[part 2 of 5: package /IBNvBlkSWC_4]
AUTOSAR XML (schema 00050)
package /IBNvBlkSWC_4  (continued)
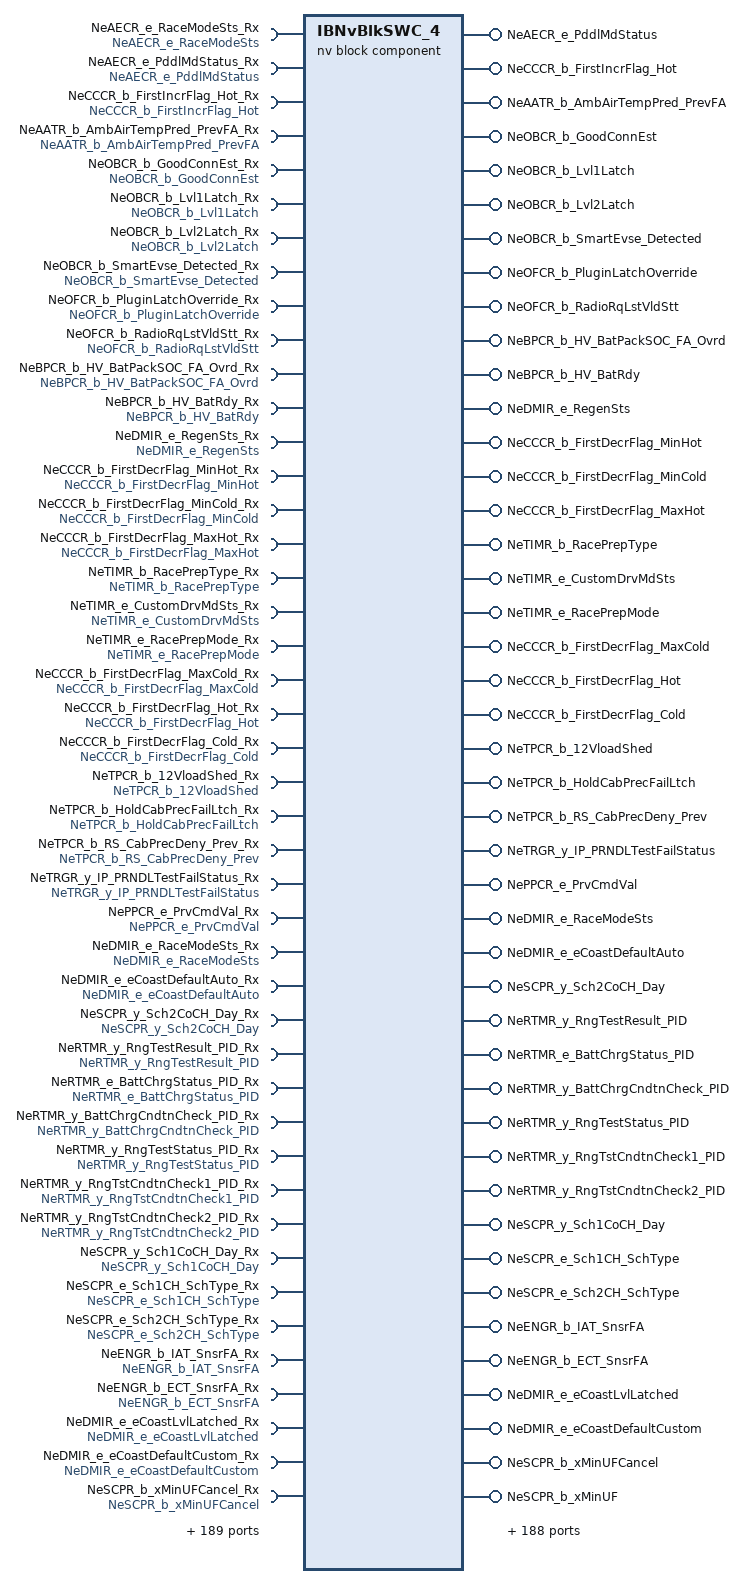
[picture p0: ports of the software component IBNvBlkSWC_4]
  nv block sw component type IBNvBlkSWC_4  (continued)
    require port NeAECR_e_RaceModeSts_Rx: nv-require-com-spec{init-value=Value:0, variable=NeAECR_e_RaceModeSts}, required-interface=NeAECR_e_RaceModeSts
    provide port NeAECR_e_PddlMdStatus: nv-provide-com-spec{ram-block-init-value=Value:0, rom-block-init-value=Value:0, variable=NeAECR_e_PddlMdStatus}, provided-interface=NeAECR_e_PddlMdStatus
    require port NeAECR_e_PddlMdStatus_Rx: nv-require-com-spec{init-value=Value:0, variable=NeAECR_e_PddlMdStatus}, required-interface=NeAECR_e_PddlMdStatus
    provide port NeCCCR_b_FirstIncrFlag_Hot: nv-provide-com-spec{ram-block-init-value=Value:0, rom-block-init-value=Value:0, variable=NeCCCR_b_FirstIncrFlag_Hot}, provided-interface=NeCCCR_b_FirstIncrFlag_Hot
    require port NeCCCR_b_FirstIncrFlag_Hot_Rx: nv-require-com-spec{init-value=Value:0, variable=NeCCCR_b_FirstIncrFlag_Hot}, required-interface=NeCCCR_b_FirstIncrFlag_Hot
    provide port NeAATR_b_AmbAirTempPred_PrevFA: nv-provide-com-spec{ram-block-init-value=Value:1, rom-block-init-value=Value:1, variable=NeAATR_b_AmbAirTempPred_PrevFA}, provided-interface=NeAATR_b_AmbAirTempPred_PrevFA
    require port NeAATR_b_AmbAirTempPred_PrevFA_Rx: nv-require-com-spec{init-value=Value:1, variable=NeAATR_b_AmbAirTempPred_PrevFA}, required-interface=NeAATR_b_AmbAirTempPred_PrevFA
    provide port NeOBCR_b_GoodConnEst: nv-provide-com-spec{ram-block-init-value=Value:1, rom-block-init-value=Value:1, variable=NeOBCR_b_GoodConnEst}, provided-interface=NeOBCR_b_GoodConnEst
    require port NeOBCR_b_GoodConnEst_Rx: nv-require-com-spec{init-value=Value:1, variable=NeOBCR_b_GoodConnEst}, required-interface=NeOBCR_b_GoodConnEst
    provide port NeOBCR_b_Lvl1Latch: nv-provide-com-spec{ram-block-init-value=Value:1, rom-block-init-value=Value:1, variable=NeOBCR_b_Lvl1Latch}, provided-interface=NeOBCR_b_Lvl1Latch
    require port NeOBCR_b_Lvl1Latch_Rx: nv-require-com-spec{init-value=Value:1, variable=NeOBCR_b_Lvl1Latch}, required-interface=NeOBCR_b_Lvl1Latch
    provide port NeOBCR_b_Lvl2Latch: nv-provide-com-spec{ram-block-init-value=Value:1, rom-block-init-value=Value:1, variable=NeOBCR_b_Lvl2Latch}, provided-interface=NeOBCR_b_Lvl2Latch
    require port NeOBCR_b_Lvl2Latch_Rx: nv-require-com-spec{init-value=Value:1, variable=NeOBCR_b_Lvl2Latch}, required-interface=NeOBCR_b_Lvl2Latch
    provide port NeOBCR_b_SmartEvse_Detected: nv-provide-com-spec{ram-block-init-value=Value:1, rom-block-init-value=Value:1, variable=NeOBCR_b_SmartEvse_Detected}, provided-interface=NeOBCR_b_SmartEvse_Detected
    require port NeOBCR_b_SmartEvse_Detected_Rx: nv-require-com-spec{init-value=Value:1, variable=NeOBCR_b_SmartEvse_Detected}, required-interface=NeOBCR_b_SmartEvse_Detected
    provide port NeOFCR_b_PluginLatchOverride: nv-provide-com-spec{ram-block-init-value=Value:0, rom-block-init-value=Value:0, variable=NeOFCR_b_PluginLatchOverride}, provided-interface=NeOFCR_b_PluginLatchOverride
    require port NeOFCR_b_PluginLatchOverride_Rx: nv-require-com-spec{init-value=Value:0, variable=NeOFCR_b_PluginLatchOverride}, required-interface=NeOFCR_b_PluginLatchOverride
    provide port NeOFCR_b_RadioRqLstVldStt: nv-provide-com-spec{ram-block-init-value=Value:0, rom-block-init-value=Value:0, variable=NeOFCR_b_RadioRqLstVldStt}, provided-interface=NeOFCR_b_RadioRqLstVldStt
    require port NeOFCR_b_RadioRqLstVldStt_Rx: nv-require-com-spec{init-value=Value:0, variable=NeOFCR_b_RadioRqLstVldStt}, required-interface=NeOFCR_b_RadioRqLstVldStt
    provide port NeBPCR_b_HV_BatPackSOC_FA_Ovrd: nv-provide-com-spec{ram-block-init-value=Value:1, rom-block-init-value=Value:1, variable=NeBPCR_b_HV_BatPackSOC_FA_Ovrd}, provided-interface=NeBPCR_b_HV_BatPackSOC_FA_Ovrd
    require port NeBPCR_b_HV_BatPackSOC_FA_Ovrd_Rx: nv-require-com-spec{init-value=Value:1, variable=NeBPCR_b_HV_BatPackSOC_FA_Ovrd}, required-interface=NeBPCR_b_HV_BatPackSOC_FA_Ovrd
    provide port NeBPCR_b_HV_BatRdy: nv-provide-com-spec{ram-block-init-value=Value:1, rom-block-init-value=Value:1, variable=NeBPCR_b_HV_BatRdy}, provided-interface=NeBPCR_b_HV_BatRdy
    require port NeBPCR_b_HV_BatRdy_Rx: nv-require-com-spec{init-value=Value:1, variable=NeBPCR_b_HV_BatRdy}, required-interface=NeBPCR_b_HV_BatRdy
    provide port NeDMIR_e_RegenSts: nv-provide-com-spec{ram-block-init-value=Value:0, rom-block-init-value=Value:0, variable=NeDMIR_e_RegenSts}, provided-interface=NeDMIR_e_RegenSts
    require port NeDMIR_e_RegenSts_Rx: nv-require-com-spec{init-value=Value:0, variable=NeDMIR_e_RegenSts}, required-interface=NeDMIR_e_RegenSts
    provide port NeCCCR_b_FirstDecrFlag_MinHot: nv-provide-com-spec{ram-block-init-value=Value:0, rom-block-init-value=Value:0, variable=NeCCCR_b_FirstDecrFlag_MinHot}, provided-interface=NeCCCR_b_FirstDecrFlag_MinHot
    require port NeCCCR_b_FirstDecrFlag_MinHot_Rx: nv-require-com-spec{init-value=Value:0, variable=NeCCCR_b_FirstDecrFlag_MinHot}, required-interface=NeCCCR_b_FirstDecrFlag_MinHot
    provide port NeCCCR_b_FirstDecrFlag_MinCold: nv-provide-com-spec{ram-block-init-value=Value:0, rom-block-init-value=Value:0, variable=NeCCCR_b_FirstDecrFlag_MinCold}, provided-interface=NeCCCR_b_FirstDecrFlag_MinCold
    require port NeCCCR_b_FirstDecrFlag_MinCold_Rx: nv-require-com-spec{init-value=Value:0, variable=NeCCCR_b_FirstDecrFlag_MinCold}, required-interface=NeCCCR_b_FirstDecrFlag_MinCold
    provide port NeCCCR_b_FirstDecrFlag_MaxHot: nv-provide-com-spec{ram-block-init-value=Value:0, rom-block-init-value=Value:0, variable=NeCCCR_b_FirstDecrFlag_MaxHot}, provided-interface=NeCCCR_b_FirstDecrFlag_MaxHot
    require port NeCCCR_b_FirstDecrFlag_MaxHot_Rx: nv-require-com-spec{init-value=Value:0, variable=NeCCCR_b_FirstDecrFlag_MaxHot}, required-interface=NeCCCR_b_FirstDecrFlag_MaxHot
    provide port NeTIMR_b_RacePrepType: nv-provide-com-spec{ram-block-init-value=Value:0, rom-block-init-value=Value:0, variable=NeTIMR_b_RacePrepType}, provided-interface=NeTIMR_b_RacePrepType
    require port NeTIMR_b_RacePrepType_Rx: nv-require-com-spec{init-value=Value:0, variable=NeTIMR_b_RacePrepType}, required-interface=NeTIMR_b_RacePrepType
    provide port NeTIMR_e_CustomDrvMdSts: nv-provide-com-spec{ram-block-init-value=Value:0, rom-block-init-value=Value:0, variable=NeTIMR_e_CustomDrvMdSts}, provided-interface=NeTIMR_e_CustomDrvMdSts
    require port NeTIMR_e_CustomDrvMdSts_Rx: nv-require-com-spec{init-value=Value:0, variable=NeTIMR_e_CustomDrvMdSts}, required-interface=NeTIMR_e_CustomDrvMdSts
    provide port NeTIMR_e_RacePrepMode: nv-provide-com-spec{ram-block-init-value=Value:0, rom-block-init-value=Value:0, variable=NeTIMR_e_RacePrepMode}, provided-interface=NeTIMR_e_RacePrepMode
    require port NeTIMR_e_RacePrepMode_Rx: nv-require-com-spec{init-value=Value:0, variable=NeTIMR_e_RacePrepMode}, required-interface=NeTIMR_e_RacePrepMode
    provide port NeCCCR_b_FirstDecrFlag_MaxCold: nv-provide-com-spec{ram-block-init-value=Value:0, rom-block-init-value=Value:0, variable=NeCCCR_b_FirstDecrFlag_MaxCold}, provided-interface=NeCCCR_b_FirstDecrFlag_MaxCold
    require port NeCCCR_b_FirstDecrFlag_MaxCold_Rx: nv-require-com-spec{init-value=Value:0, variable=NeCCCR_b_FirstDecrFlag_MaxCold}, required-interface=NeCCCR_b_FirstDecrFlag_MaxCold
    provide port NeCCCR_b_FirstDecrFlag_Hot: nv-provide-com-spec{ram-block-init-value=Value:0, rom-block-init-value=Value:0, variable=NeCCCR_b_FirstDecrFlag_Hot}, provided-interface=NeCCCR_b_FirstDecrFlag_Hot
    require port NeCCCR_b_FirstDecrFlag_Hot_Rx: nv-require-com-spec{init-value=Value:0, variable=NeCCCR_b_FirstDecrFlag_Hot}, required-interface=NeCCCR_b_FirstDecrFlag_Hot
    provide port NeCCCR_b_FirstDecrFlag_Cold: nv-provide-com-spec{ram-block-init-value=Value:0, rom-block-init-value=Value:0, variable=NeCCCR_b_FirstDecrFlag_Cold}, provided-interface=NeCCCR_b_FirstDecrFlag_Cold
    require port NeCCCR_b_FirstDecrFlag_Cold_Rx: nv-require-com-spec{init-value=Value:0, variable=NeCCCR_b_FirstDecrFlag_Cold}, required-interface=NeCCCR_b_FirstDecrFlag_Cold
    provide port NeTPCR_b_12VloadShed: nv-provide-com-spec{ram-block-init-value=Value:1, rom-block-init-value=Value:1, variable=NeTPCR_b_12VloadShed}, provided-interface=NeTPCR_b_12VloadShed
    require port NeTPCR_b_12VloadShed_Rx: nv-require-com-spec{init-value=Value:1, variable=NeTPCR_b_12VloadShed}, required-interface=NeTPCR_b_12VloadShed
    provide port NeTPCR_b_HoldCabPrecFailLtch: nv-provide-com-spec{ram-block-init-value=Value:1, rom-block-init-value=Value:1, variable=NeTPCR_b_HoldCabPrecFailLtch}, provided-interface=NeTPCR_b_HoldCabPrecFailLtch
    require port NeTPCR_b_HoldCabPrecFailLtch_Rx: nv-require-com-spec{init-value=Value:1, variable=NeTPCR_b_HoldCabPrecFailLtch}, required-interface=NeTPCR_b_HoldCabPrecFailLtch
    provide port NeTPCR_b_RS_CabPrecDeny_Prev: nv-provide-com-spec{ram-block-init-value=Value:1, rom-block-init-value=Value:1, variable=NeTPCR_b_RS_CabPrecDeny_Prev}, provided-interface=NeTPCR_b_RS_CabPrecDeny_Prev
    require port NeTPCR_b_RS_CabPrecDeny_Prev_Rx: nv-require-com-spec{init-value=Value:1, variable=NeTPCR_b_RS_CabPrecDeny_Prev}, required-interface=NeTPCR_b_RS_CabPrecDeny_Prev
    provide port NeTRGR_y_IP_PRNDLTestFailStatus: nv-provide-com-spec{ram-block-init-value=Value:0, rom-block-init-value=Value:0, variable=NeTRGR_y_IP_PRNDLTestFailStatus}, provided-interface=NeTRGR_y_IP_PRNDLTestFailStatus
    require port NeTRGR_y_IP_PRNDLTestFailStatus_Rx: nv-require-com-spec{init-value=Value:0, variable=NeTRGR_y_IP_PRNDLTestFailStatus}, required-interface=NeTRGR_y_IP_PRNDLTestFailStatus
    provide port NePPCR_e_PrvCmdVal: nv-provide-com-spec{ram-block-init-value=Value:255, rom-block-init-value=Value:255, variable=NePPCR_e_PrvCmdVal}, provided-interface=NePPCR_e_PrvCmdVal
    require port NePPCR_e_PrvCmdVal_Rx: nv-require-com-spec{init-value=Value:255, variable=NePPCR_e_PrvCmdVal}, required-interface=NePPCR_e_PrvCmdVal
    provide port NeDMIR_e_RaceModeSts: nv-provide-com-spec{ram-block-init-value=Value:0, rom-block-init-value=Value:0, variable=NeDMIR_e_RaceModeSts}, provided-interface=NeDMIR_e_RaceModeSts
    require port NeDMIR_e_RaceModeSts_Rx: nv-require-com-spec{init-value=Value:0, variable=NeDMIR_e_RaceModeSts}, required-interface=NeDMIR_e_RaceModeSts
    provide port NeDMIR_e_eCoastDefaultAuto: nv-provide-com-spec{ram-block-init-value=Value:0, rom-block-init-value=Value:0, variable=NeDMIR_e_eCoastDefaultAuto}, provided-interface=NeDMIR_e_eCoastDefaultAuto
    require port NeDMIR_e_eCoastDefaultAuto_Rx: nv-require-com-spec{init-value=Value:0, variable=NeDMIR_e_eCoastDefaultAuto}, required-interface=NeDMIR_e_eCoastDefaultAuto
    provide port NeSCPR_y_Sch2CoCH_Day: nv-provide-com-spec{ram-block-init-value=Value:0, rom-block-init-value=Value:0, variable=NeSCPR_y_Sch2CoCH_Day}, provided-interface=NeSCPR_y_Sch2CoCH_Day
    require port NeSCPR_y_Sch2CoCH_Day_Rx: nv-require-com-spec{init-value=Value:0, variable=NeSCPR_y_Sch2CoCH_Day}, required-interface=NeSCPR_y_Sch2CoCH_Day
    provide port NeRTMR_y_RngTestResult_PID: nv-provide-com-spec{ram-block-init-value=Value:0, rom-block-init-value=Value:0, variable=NeRTMR_y_RngTestResult_PID}, provided-interface=NeRTMR_y_RngTestResult_PID
    require port NeRTMR_y_RngTestResult_PID_Rx: nv-require-com-spec{init-value=Value:0, variable=NeRTMR_y_RngTestResult_PID}, required-interface=NeRTMR_y_RngTestResult_PID
    provide port NeRTMR_e_BattChrgStatus_PID: nv-provide-com-spec{ram-block-init-value=Value:0, rom-block-init-value=Value:0, variable=NeRTMR_e_BattChrgStatus_PID}, provided-interface=NeRTMR_e_BattChrgStatus_PID
    require port NeRTMR_e_BattChrgStatus_PID_Rx: nv-require-com-spec{init-value=Value:0, variable=NeRTMR_e_BattChrgStatus_PID}, required-interface=NeRTMR_e_BattChrgStatus_PID
    provide port NeRTMR_y_BattChrgCndtnCheck_PID: nv-provide-com-spec{ram-block-init-value=Value:0, rom-block-init-value=Value:0, variable=NeRTMR_y_BattChrgCndtnCheck_PID}, provided-interface=NeRTMR_y_BattChrgCndtnCheck_PID
    require port NeRTMR_y_BattChrgCndtnCheck_PID_Rx: nv-require-com-spec{init-value=Value:0, variable=NeRTMR_y_BattChrgCndtnCheck_PID}, required-interface=NeRTMR_y_BattChrgCndtnCheck_PID
    provide port NeRTMR_y_RngTestStatus_PID: nv-provide-com-spec{ram-block-init-value=Value:0, rom-block-init-value=Value:0, variable=NeRTMR_y_RngTestStatus_PID}, provided-interface=NeRTMR_y_RngTestStatus_PID
    require port NeRTMR_y_RngTestStatus_PID_Rx: nv-require-com-spec{init-value=Value:0, variable=NeRTMR_y_RngTestStatus_PID}, required-interface=NeRTMR_y_RngTestStatus_PID
    provide port NeRTMR_y_RngTstCndtnCheck1_PID: nv-provide-com-spec{ram-block-init-value=Value:0, rom-block-init-value=Value:0, variable=NeRTMR_y_RngTstCndtnCheck1_PID}, provided-interface=NeRTMR_y_RngTstCndtnCheck1_PID
    require port NeRTMR_y_RngTstCndtnCheck1_PID_Rx: nv-require-com-spec{init-value=Value:0, variable=NeRTMR_y_RngTstCndtnCheck1_PID}, required-interface=NeRTMR_y_RngTstCndtnCheck1_PID
    provide port NeRTMR_y_RngTstCndtnCheck2_PID: nv-provide-com-spec{ram-block-init-value=Value:0, rom-block-init-value=Value:0, variable=NeRTMR_y_RngTstCndtnCheck2_PID}, provided-interface=NeRTMR_y_RngTstCndtnCheck2_PID
    require port NeRTMR_y_RngTstCndtnCheck2_PID_Rx: nv-require-com-spec{init-value=Value:0, variable=NeRTMR_y_RngTstCndtnCheck2_PID}, required-interface=NeRTMR_y_RngTstCndtnCheck2_PID
    provide port NeSCPR_y_Sch1CoCH_Day: nv-provide-com-spec{ram-block-init-value=Value:0, rom-block-init-value=Value:0, variable=NeSCPR_y_Sch1CoCH_Day}, provided-interface=NeSCPR_y_Sch1CoCH_Day
    require port NeSCPR_y_Sch1CoCH_Day_Rx: nv-require-com-spec{init-value=Value:0, variable=NeSCPR_y_Sch1CoCH_Day}, required-interface=NeSCPR_y_Sch1CoCH_Day
    provide port NeSCPR_e_Sch1CH_SchType: nv-provide-com-spec{ram-block-init-value=Value:0, rom-block-init-value=Value:0, variable=NeSCPR_e_Sch1CH_SchType}, provided-interface=NeSCPR_e_Sch1CH_SchType
    require port NeSCPR_e_Sch1CH_SchType_Rx: nv-require-com-spec{init-value=Value:0, variable=NeSCPR_e_Sch1CH_SchType}, required-interface=NeSCPR_e_Sch1CH_SchType
    provide port NeSCPR_e_Sch2CH_SchType: nv-provide-com-spec{ram-block-init-value=Value:0, rom-block-init-value=Value:0, variable=NeSCPR_e_Sch2CH_SchType}, provided-interface=NeSCPR_e_Sch2CH_SchType
    require port NeSCPR_e_Sch2CH_SchType_Rx: nv-require-com-spec{init-value=Value:0, variable=NeSCPR_e_Sch2CH_SchType}, required-interface=NeSCPR_e_Sch2CH_SchType
    provide port NeENGR_b_IAT_SnsrFA: nv-provide-com-spec{ram-block-init-value=Value:0, rom-block-init-value=Value:0, variable=NeENGR_b_IAT_SnsrFA}, provided-interface=NeENGR_b_IAT_SnsrFA
    require port NeENGR_b_IAT_SnsrFA_Rx: nv-require-com-spec{init-value=Value:0, variable=NeENGR_b_IAT_SnsrFA}, required-interface=NeENGR_b_IAT_SnsrFA
    provide port NeENGR_b_ECT_SnsrFA: nv-provide-com-spec{ram-block-init-value=Value:0, rom-block-init-value=Value:0, variable=NeENGR_b_ECT_SnsrFA}, provided-interface=NeENGR_b_ECT_SnsrFA
    require port NeENGR_b_ECT_SnsrFA_Rx: nv-require-com-spec{init-value=Value:0, variable=NeENGR_b_ECT_SnsrFA}, required-interface=NeENGR_b_ECT_SnsrFA
    provide port NeDMIR_e_eCoastLvlLatched: nv-provide-com-spec{ram-block-init-value=Value:0, rom-block-init-value=Value:0, variable=NeDMIR_e_eCoastLvlLatched}, provided-interface=NeDMIR_e_eCoastLvlLatched
    require port NeDMIR_e_eCoastLvlLatched_Rx: nv-require-com-spec{init-value=Value:0, variable=NeDMIR_e_eCoastLvlLatched}, required-interface=NeDMIR_e_eCoastLvlLatched
    provide port NeDMIR_e_eCoastDefaultCustom: nv-provide-com-spec{ram-block-init-value=Value:0, rom-block-init-value=Value:0, variable=NeDMIR_e_eCoastDefaultCustom}, provided-interface=NeDMIR_e_eCoastDefaultCustom
    require port NeDMIR_e_eCoastDefaultCustom_Rx: nv-require-com-spec{init-value=Value:0, variable=NeDMIR_e_eCoastDefaultCustom}, required-interface=NeDMIR_e_eCoastDefaultCustom
    provide port NeSCPR_b_xMinUFCancel: nv-provide-com-spec{ram-block-init-value=Value:0, rom-block-init-value=Value:0, variable=NeSCPR_b_xMinUFCancel}, provided-interface=NeSCPR_b_xMinUFCancel
    require port NeSCPR_b_xMinUFCancel_Rx: nv-require-com-spec{init-value=Value:0, variable=NeSCPR_b_xMinUFCancel}, required-interface=NeSCPR_b_xMinUFCancel
    provide port NeSCPR_b_xMinUF: nv-provide-com-spec{ram-block-init-value=Value:0, rom-block-init-value=Value:0, variable=NeSCPR_b_xMinUF}, provided-interface=NeSCPR_b_xMinUF
    require port NeSCPR_b_xMinUF_Rx: nv-require-com-spec{init-value=Value:0, variable=NeSCPR_b_xMinUF}, required-interface=NeSCPR_b_xMinUF
    provide port NeSCPR_b_StopChrg: nv-provide-com-spec{ram-block-init-value=Value:0, rom-block-init-value=Value:0, variable=NeSCPR_b_StopChrg}, provided-interface=NeSCPR_b_StopChrg
    require port NeSCPR_b_StopChrg_Rx: nv-require-com-spec{init-value=Value:0, variable=NeSCPR_b_StopChrg}, required-interface=NeSCPR_b_StopChrg
    provide port NeSCPR_b_Sch2CoCH_Enbl: nv-provide-com-spec{ram-block-init-value=Value:0, rom-block-init-value=Value:0, variable=NeSCPR_b_Sch2CoCH_Enbl}, provided-interface=NeSCPR_b_Sch2CoCH_Enbl
    require port NeSCPR_b_Sch2CoCH_Enbl_Rx: nv-require-com-spec{init-value=Value:0, variable=NeSCPR_b_Sch2CoCH_Enbl}, required-interface=NeSCPR_b_Sch2CoCH_Enbl
    provide port NeHVTR_b_AntiTampFailed: nv-provide-com-spec{ram-block-init-value=Value:0, rom-block-init-value=Value:0, variable=NeHVTR_b_AntiTampFailed}, provided-interface=NeHVTR_b_AntiTampFailed
    require port NeHVTR_b_AntiTampFailed_Rx: nv-require-com-spec{init-value=Value:0, variable=NeHVTR_b_AntiTampFailed}, required-interface=NeHVTR_b_AntiTampFailed
    provide port NeSCPR_b_AllowCancel: nv-provide-com-spec{ram-block-init-value=Value:0, rom-block-init-value=Value:0, variable=NeSCPR_b_AllowCancel}, provided-interface=NeSCPR_b_AllowCancel
    require port NeSCPR_b_AllowCancel_Rx: nv-require-com-spec{init-value=Value:0, variable=NeSCPR_b_AllowCancel}, required-interface=NeSCPR_b_AllowCancel
    provide port NeSCPR_b_CancSchedIsUF: nv-provide-com-spec{ram-block-init-value=Value:0, rom-block-init-value=Value:0, variable=NeSCPR_b_CancSchedIsUF}, provided-interface=NeSCPR_b_CancSchedIsUF
    require port NeSCPR_b_CancSchedIsUF_Rx: nv-require-com-spec{init-value=Value:0, variable=NeSCPR_b_CancSchedIsUF}, required-interface=NeSCPR_b_CancSchedIsUF
    provide port NeSCPR_b_CancWindow: nv-provide-com-spec{ram-block-init-value=Value:0, rom-block-init-value=Value:0, variable=NeSCPR_b_CancWindow}, provided-interface=NeSCPR_b_CancWindow
    require port NeSCPR_b_CancWindow_Rx: nv-require-com-spec{init-value=Value:0, variable=NeSCPR_b_CancWindow}, required-interface=NeSCPR_b_CancWindow
    provide port NeSCPR_b_ChrgComplete: nv-provide-com-spec{ram-block-init-value=Value:0, rom-block-init-value=Value:0, variable=NeSCPR_b_ChrgComplete}, provided-interface=NeSCPR_b_ChrgComplete
    require port NeSCPR_b_ChrgComplete_Rx: nv-require-com-spec{init-value=Value:0, variable=NeSCPR_b_ChrgComplete}, required-interface=NeSCPR_b_ChrgComplete
    provide port NeSCPR_b_CoCH_Sch1_DNR: nv-provide-com-spec{ram-block-init-value=Value:0, rom-block-init-value=Value:0, variable=NeSCPR_b_CoCH_Sch1_DNR}, provided-interface=NeSCPR_b_CoCH_Sch1_DNR
    require port NeSCPR_b_CoCH_Sch1_DNR_Rx: nv-require-com-spec{init-value=Value:0, variable=NeSCPR_b_CoCH_Sch1_DNR}, required-interface=NeSCPR_b_CoCH_Sch1_DNR
    provide port NeSCPR_b_CoCH_Sch2_DNR: nv-provide-com-spec{ram-block-init-value=Value:0, rom-block-init-value=Value:0, variable=NeSCPR_b_CoCH_Sch2_DNR}, provided-interface=NeSCPR_b_CoCH_Sch2_DNR
    require port NeSCPR_b_CoCH_Sch2_DNR_Rx: nv-require-com-spec{init-value=Value:0, variable=NeSCPR_b_CoCH_Sch2_DNR}, required-interface=NeSCPR_b_CoCH_Sch2_DNR
    provide port NeSCPR_b_CoCh_VehLocation: nv-provide-com-spec{ram-block-init-value=Value:0, rom-block-init-value=Value:0, variable=NeSCPR_b_CoCh_VehLocation}, provided-interface=NeSCPR_b_CoCh_VehLocation
    require port NeSCPR_b_CoCh_VehLocation_Rx: nv-require-com-spec{init-value=Value:0, variable=NeSCPR_b_CoCh_VehLocation}, required-interface=NeSCPR_b_CoCh_VehLocation
    provide port NeSCPR_b_PluginLatchOverride: nv-provide-com-spec{ram-block-init-value=Value:0, rom-block-init-value=Value:0, variable=NeSCPR_b_PluginLatchOverride}, provided-interface=NeSCPR_b_PluginLatchOverride
    require port NeSCPR_b_PluginLatchOverride_Rx: nv-require-com-spec{init-value=Value:0, variable=NeSCPR_b_PluginLatchOverride}, required-interface=NeSCPR_b_PluginLatchOverride
    provide port NeSCPR_b_RadioRqLstVldStt: nv-provide-com-spec{ram-block-init-value=Value:0, rom-block-init-value=Value:0, variable=NeSCPR_b_RadioRqLstVldStt}, provided-interface=NeSCPR_b_RadioRqLstVldStt
    require port NeSCPR_b_RadioRqLstVldStt_Rx: nv-require-com-spec{init-value=Value:0, variable=NeSCPR_b_RadioRqLstVldStt}, required-interface=NeSCPR_b_RadioRqLstVldStt
    provide port NeSCPR_b_Sch1CoCH_Enbl: nv-provide-com-spec{ram-block-init-value=Value:0, rom-block-init-value=Value:0, variable=NeSCPR_b_Sch1CoCH_Enbl}, provided-interface=NeSCPR_b_Sch1CoCH_Enbl
    require port NeSCPR_b_Sch1CoCH_Enbl_Rx: nv-require-com-spec{init-value=Value:0, variable=NeSCPR_b_Sch1CoCH_Enbl}, required-interface=NeSCPR_b_Sch1CoCH_Enbl
    provide port EePLTR_t_RTCTime: nv-provide-com-spec{ram-block-init-value=Value:0, rom-block-init-value=Value:0, variable=EePLTR_t_RTCTime}, provided-interface=EePLTR_t_RTCTime
    require port EePLTR_t_RTCTime_Rx: nv-require-com-spec{init-value=Value:0, variable=EePLTR_t_RTCTime}, required-interface=EePLTR_t_RTCTime
    provide port EeHCDR_t_RealTime_Comp_On: nv-provide-com-spec{ram-block-init-value=Value:0, rom-block-init-value=Value:0, variable=EeHCDR_t_RealTime_Comp_On}, provided-interface=EeHCDR_t_RealTime_Comp_On
    require port EeHCDR_t_RealTime_Comp_On_Rx: nv-require-com-spec{init-value=Value:0, variable=EeHCDR_t_RealTime_Comp_On}, required-interface=EeHCDR_t_RealTime_Comp_On
    provide port EeHCDR_t_RealTime_Comp_Off: nv-provide-com-spec{ram-block-init-value=Value:0, rom-block-init-value=Value:0, variable=EeHCDR_t_RealTime_Comp_Off}, provided-interface=EeHCDR_t_RealTime_Comp_Off
    require port EeHCDR_t_RealTime_Comp_Off_Rx: nv-require-com-spec{init-value=Value:0, variable=EeHCDR_t_RealTime_Comp_Off}, required-interface=EeHCDR_t_RealTime_Comp_Off
    provide port EeERER_l_EEPROM_EstRange: nv-provide-com-spec{ram-block-init-value=Value:0, rom-block-init-value=Value:0, variable=EeERER_l_EEPROM_EstRange}, provided-interface=EeERER_l_EEPROM_EstRange
    require port EeERER_l_EEPROM_EstRange_Rx: nv-require-com-spec{init-value=Value:0, variable=EeERER_l_EEPROM_EstRange}, required-interface=EeERER_l_EEPROM_EstRange
    provide port EeDCCR_t_V2GPerfInhibTime: nv-provide-com-spec{ram-block-init-value=Value:0, rom-block-init-value=Value:0, variable=EeDCCR_t_V2GPerfInhibTime}, provided-interface=EeDCCR_t_V2GPerfInhibTime
    require port EeDCCR_t_V2GPerfInhibTime_Rx: nv-require-com-spec{init-value=Value:0, variable=EeDCCR_t_V2GPerfInhibTime}, required-interface=EeDCCR_t_V2GPerfInhibTime
    provide port EeDCCR_t_V2GTime: nv-provide-com-spec{ram-block-init-value=Value:0, rom-block-init-value=Value:0, variable=EeDCCR_t_V2GTime}, provided-interface=EeDCCR_t_V2GTime
    require port EeDCCR_t_V2GTime_Rx: nv-require-com-spec{init-value=Value:0, variable=EeDCCR_t_V2GTime}, required-interface=EeDCCR_t_V2GTime
    provide port EeERER_F_EEPROM_WhperKM: nv-provide-com-spec{ram-block-init-value=Value:0, rom-block-init-value=Value:0, variable=EeERER_F_EEPROM_WhperKM}, provided-interface=EeERER_F_EEPROM_WhperKM
    require port EeERER_F_EEPROM_WhperKM_Rx: nv-require-com-spec{init-value=Value:0, variable=EeERER_F_EEPROM_WhperKM}, required-interface=EeERER_F_EEPROM_WhperKM
    provide port EeERER_k_Modify_Factor: nv-provide-com-spec{ram-block-init-value=Value:0, rom-block-init-value=Value:0, variable=EeERER_k_Modify_Factor}, provided-interface=EeERER_k_Modify_Factor
    require port EeERER_k_Modify_Factor_Rx: nv-require-com-spec{init-value=Value:0, variable=EeERER_k_Modify_Factor}, required-interface=EeERER_k_Modify_Factor
    provide port EeERER_l_VehDist_Delta: nv-provide-com-spec{ram-block-init-value=Value:0, rom-block-init-value=Value:0, variable=EeERER_l_VehDist_Delta}, provided-interface=EeERER_l_VehDist_Delta
    require port EeERER_l_VehDist_Delta_Rx: nv-require-com-spec{init-value=Value:0, variable=EeERER_l_VehDist_Delta}, required-interface=EeERER_l_VehDist_Delta
    provide port EePWDR_t_DAP_FA_InitTime: nv-provide-com-spec{ram-block-init-value=Value:0, rom-block-init-value=Value:0, variable=EePWDR_t_DAP_FA_InitTime}, provided-interface=EePWDR_t_DAP_FA_InitTime
    require port EePWDR_t_DAP_FA_InitTime_Rx: nv-require-com-spec{init-value=Value:0, variable=EePWDR_t_DAP_FA_InitTime}, required-interface=EePWDR_t_DAP_FA_InitTime
    provide port EePWDR_t_DAP_FA_ElapsedTime: nv-provide-com-spec{ram-block-init-value=Value:0, rom-block-init-value=Value:0, variable=EePWDR_t_DAP_FA_ElapsedTime}, provided-interface=EePWDR_t_DAP_FA_ElapsedTime
    require port EePWDR_t_DAP_FA_ElapsedTime_Rx: nv-require-com-spec{init-value=Value:0, variable=EePWDR_t_DAP_FA_ElapsedTime}, required-interface=EePWDR_t_DAP_FA_ElapsedTime
    provide port EePWDR_l_DAP_FA_DistTravld: nv-provide-com-spec{ram-block-init-value=Value:0, rom-block-init-value=Value:0, variable=EePWDR_l_DAP_FA_DistTravld}, provided-interface=EePWDR_l_DAP_FA_DistTravld
    require port EePWDR_l_DAP_FA_DistTravld_Rx: nv-require-com-spec{init-value=Value:0, variable=EePWDR_l_DAP_FA_DistTravld}, required-interface=EePWDR_l_DAP_FA_DistTravld
    provide port EeOBCR_t_EstTimeofChrg_Lv1: nv-provide-com-spec{ram-block-init-value=Value:4294967295, rom-block-init-value=Value:4294967295, variable=EeOBCR_t_EstTimeofChrg_Lv1}, provided-interface=EeOBCR_t_EstTimeofChrg_Lv1
    require port EeOBCR_t_EstTimeofChrg_Lv1_Rx: nv-require-com-spec{init-value=Value:4294967295, variable=EeOBCR_t_EstTimeofChrg_Lv1}, required-interface=EeOBCR_t_EstTimeofChrg_Lv1
    provide port EeOBCR_t_EstTimeofChrg_Lv2: nv-provide-com-spec{ram-block-init-value=Value:4294967295, rom-block-init-value=Value:4294967295, variable=EeOBCR_t_EstTimeofChrg_Lv2}, provided-interface=EeOBCR_t_EstTimeofChrg_Lv2
    require port EeOBCR_t_EstTimeofChrg_Lv2_Rx: nv-require-com-spec{init-value=Value:4294967295, variable=EeOBCR_t_EstTimeofChrg_Lv2}, required-interface=EeOBCR_t_EstTimeofChrg_Lv2
    provide port EeIMOR_M_Rand1_prev: nv-provide-com-spec{ram-block-init-value=Value:4294967295, rom-block-init-value=Value:4294967295, variable=EeIMOR_M_Rand1_prev}, provided-interface=EeIMOR_M_Rand1_prev
    require port EeIMOR_M_Rand1_prev_Rx: nv-require-com-spec{init-value=Value:4294967295, variable=EeIMOR_M_Rand1_prev}, required-interface=EeIMOR_M_Rand1_prev
    provide port EeIMOR_M_Rand2_prev: nv-provide-com-spec{ram-block-init-value=Value:4294967295, rom-block-init-value=Value:4294967295, variable=EeIMOR_M_Rand2_prev}, provided-interface=EeIMOR_M_Rand2_prev
    require port EeIMOR_M_Rand2_prev_Rx: nv-require-com-spec{init-value=Value:4294967295, variable=EeIMOR_M_Rand2_prev}, required-interface=EeIMOR_M_Rand2_prev
    provide port EeIMOR_M_Rand3_prev: nv-provide-com-spec{ram-block-init-value=Value:4294967295, rom-block-init-value=Value:4294967295, variable=EeIMOR_M_Rand3_prev}, provided-interface=EeIMOR_M_Rand3_prev
    require port EeIMOR_M_Rand3_prev_Rx: nv-require-com-spec{init-value=Value:4294967295, variable=EeIMOR_M_Rand3_prev}, required-interface=EeIMOR_M_Rand3_prev
    provide port EeIMOR_M_Rand4_prev: nv-provide-com-spec{ram-block-init-value=Value:4294967295, rom-block-init-value=Value:4294967295, variable=EeIMOR_M_Rand4_prev}, provided-interface=EeIMOR_M_Rand4_prev
    require port EeIMOR_M_Rand4_prev_Rx: nv-require-com-spec{init-value=Value:4294967295, variable=EeIMOR_M_Rand4_prev}, required-interface=EeIMOR_M_Rand4_prev
    provide port EePLTR_t_PowerdownTime: nv-provide-com-spec{ram-block-init-value=Value:0, rom-block-init-value=Value:0, variable=EePLTR_t_PowerdownTime}, provided-interface=EePLTR_t_PowerdownTime
    require port EePLTR_t_PowerdownTime_Rx: nv-require-com-spec{init-value=Value:0, variable=EePLTR_t_PowerdownTime}, required-interface=EePLTR_t_PowerdownTime
    provide port EeTPCR_e_HoldClusterMsg: nv-provide-com-spec{ram-block-init-value=Value:32767, rom-block-init-value=Value:32767, variable=EeTPCR_e_HoldClusterMsg}, provided-interface=EeTPCR_e_HoldClusterMsg
    require port EeTPCR_e_HoldClusterMsg_Rx: nv-require-com-spec{init-value=Value:32767, variable=EeTPCR_e_HoldClusterMsg}, required-interface=EeTPCR_e_HoldClusterMsg
    provide port EeTPCR_e_HoldClusterMsg_KHC: nv-provide-com-spec{ram-block-init-value=Value:32767, rom-block-init-value=Value:32767, variable=EeTPCR_e_HoldClusterMsg_KHC}, provided-interface=EeTPCR_e_HoldClusterMsg_KHC
    require port EeTPCR_e_HoldClusterMsg_KHC_Rx: nv-require-com-spec{init-value=Value:32767, variable=EeTPCR_e_HoldClusterMsg_KHC}, required-interface=EeTPCR_e_HoldClusterMsg_KHC
    provide port EePLTR_e_ShippingMode: nv-provide-com-spec{ram-block-init-value=Value:0, rom-block-init-value=Value:0, variable=EePLTR_e_ShippingMode}, provided-interface=EePLTR_e_ShippingMode
    require port EePLTR_e_ShippingMode_Rx: nv-require-com-spec{init-value=Value:0, variable=EePLTR_e_ShippingMode}, required-interface=EePLTR_e_ShippingMode
    provide port EeDMIR_d_ChargeTypeCnf: nv-provide-com-spec{ram-block-init-value=Value:0, rom-block-init-value=Value:0, variable=EeDMIR_d_ChargeTypeCnf}, provided-interface=EeDMIR_d_ChargeTypeCnf
    require port EeDMIR_d_ChargeTypeCnf_Rx: nv-require-com-spec{init-value=Value:0, variable=EeDMIR_d_ChargeTypeCnf}, required-interface=EeDMIR_d_ChargeTypeCnf
    provide port EeDMIR_d_TgtSOCRngCnf: nv-provide-com-spec{ram-block-init-value=Value:0, rom-block-init-value=Value:0, variable=EeDMIR_d_TgtSOCRngCnf}, provided-interface=EeDMIR_d_TgtSOCRngCnf
    require port EeDMIR_d_TgtSOCRngCnf_Rx: nv-require-com-spec{init-value=Value:0, variable=EeDMIR_d_TgtSOCRngCnf}, required-interface=EeDMIR_d_TgtSOCRngCnf
    provide port EeIMOR_e_BuildAssemblyModeStat: nv-provide-com-spec{ram-block-init-value=Value:32767, rom-block-init-value=Value:32767, variable=EeIMOR_e_BuildAssemblyModeStat}, provided-interface=EeIMOR_e_BuildAssemblyModeStat
    require port EeIMOR_e_BuildAssemblyModeStat_Rx: nv-require-com-spec{init-value=Value:32767, variable=EeIMOR_e_BuildAssemblyModeStat}, required-interface=EeIMOR_e_BuildAssemblyModeStat
    provide port EeHVTR_e_StrtCmd_SrvcProc1320: nv-provide-com-spec{ram-block-init-value=Value:2, rom-block-init-value=Value:2, variable=EeHVTR_e_StrtCmd_SrvcProc1320}, provided-interface=EeHVTR_e_StrtCmd_SrvcProc1320
    require port EeHVTR_e_StrtCmd_SrvcProc1320_Rx: nv-require-com-spec{init-value=Value:2, variable=EeHVTR_e_StrtCmd_SrvcProc1320}, required-interface=EeHVTR_e_StrtCmd_SrvcProc1320
    provide port EePLTR_e_RTCStatus: nv-provide-com-spec{ram-block-init-value=Value:0, rom-block-init-value=Value:0, variable=EePLTR_e_RTCStatus}, provided-interface=EePLTR_e_RTCStatus
    require port EePLTR_e_RTCStatus_Rx: nv-require-com-spec{init-value=Value:0, variable=EePLTR_e_RTCStatus}, required-interface=EePLTR_e_RTCStatus
    provide port EeERER_e_DriveMode: nv-provide-com-spec{ram-block-init-value=Value:0, rom-block-init-value=Value:0, variable=EeERER_e_DriveMode}, provided-interface=EeERER_e_DriveMode
    require port EeERER_e_DriveMode_Rx: nv-require-com-spec{init-value=Value:0, variable=EeERER_e_DriveMode}, required-interface=EeERER_e_DriveMode
    provide port EeERER_e_TurtleMode: nv-provide-com-spec{ram-block-init-value=Value:0, rom-block-init-value=Value:0, variable=EeERER_e_TurtleMode}, provided-interface=EeERER_e_TurtleMode
    require port EeERER_e_TurtleMode_Rx: nv-require-com-spec{init-value=Value:0, variable=EeERER_e_TurtleMode}, required-interface=EeERER_e_TurtleMode
    provide port EeAECR_e_MaxRegenDsrdSt: nv-provide-com-spec{ram-block-init-value=Value:0, rom-block-init-value=Value:0, variable=EeAECR_e_MaxRegenDsrdSt}, provided-interface=EeAECR_e_MaxRegenDsrdSt
    require port EeAECR_e_MaxRegenDsrdSt_Rx: nv-require-com-spec{init-value=Value:0, variable=EeAECR_e_MaxRegenDsrdSt}, required-interface=EeAECR_e_MaxRegenDsrdSt
    provide port EeOBCR_e_ChargingSystemSts: nv-provide-com-spec{ram-block-init-value=Value:32767, rom-block-init-value=Value:32767, variable=EeOBCR_e_ChargingSystemSts}, provided-interface=EeOBCR_e_ChargingSystemSts
    require port EeOBCR_e_ChargingSystemSts_Rx: nv-require-com-spec{init-value=Value:32767, variable=EeOBCR_e_ChargingSystemSts}, required-interface=EeOBCR_e_ChargingSystemSts
    provide port EeOBCR_e_ChargingLevel: nv-provide-com-spec{ram-block-init-value=Value:32767, rom-block-init-value=Value:32767, variable=EeOBCR_e_ChargingLevel}, provided-interface=EeOBCR_e_ChargingLevel
    require port EeOBCR_e_ChargingLevel_Rx: nv-require-com-spec{init-value=Value:32767, variable=EeOBCR_e_ChargingLevel}, required-interface=EeOBCR_e_ChargingLevel
    provide port EeCHFR_b_ChrgSysFault: nv-provide-com-spec{ram-block-init-value=Value:0, rom-block-init-value=Value:0, variable=EeCHFR_b_ChrgSysFault}, provided-interface=EeCHFR_b_ChrgSysFault
    require port EeCHFR_b_ChrgSysFault_Rx: nv-require-com-spec{init-value=Value:0, variable=EeCHFR_b_ChrgSysFault}, required-interface=EeCHFR_b_ChrgSysFault
    provide port EeIMOR_y_MMKey1org22_Mem: nv-provide-com-spec{ram-block-init-value=Value:255, rom-block-init-value=Value:255, variable=EeIMOR_y_MMKey1org22_Mem}, provided-interface=EeIMOR_y_MMKey1org22_Mem
    require port EeIMOR_y_MMKey1org22_Mem_Rx: nv-require-com-spec{init-value=Value:255, variable=EeIMOR_y_MMKey1org22_Mem}, required-interface=EeIMOR_y_MMKey1org22_Mem
    provide port EeOBCR_b_PluggedIn: nv-provide-com-spec{ram-block-init-value=Value:0, rom-block-init-value=Value:0, variable=EeOBCR_b_PluggedIn}, provided-interface=EeOBCR_b_PluggedIn
    require port EeOBCR_b_PluggedIn_Rx: nv-require-com-spec{init-value=Value:0, variable=EeOBCR_b_PluggedIn}, required-interface=EeOBCR_b_PluggedIn
    provide port EePLTR_b_RTC_CurrentTimeFA: nv-provide-com-spec{ram-block-init-value=Value:0, rom-block-init-value=Value:0, variable=EePLTR_b_RTC_CurrentTimeFA}, provided-interface=EePLTR_b_RTC_CurrentTimeFA
    require port EePLTR_b_RTC_CurrentTimeFA_Rx: nv-require-com-spec{init-value=Value:0, variable=EePLTR_b_RTC_CurrentTimeFA}, required-interface=EePLTR_b_RTC_CurrentTimeFA
    provide port EeIMOR_b_AuthCmd08_InFlag: nv-provide-com-spec{ram-block-init-value=Value:0, rom-block-init-value=Value:0, variable=EeIMOR_b_AuthCmd08_InFlag}, provided-interface=EeIMOR_b_AuthCmd08_InFlag
    require port EeIMOR_b_AuthCmd08_InFlag_Rx: nv-require-com-spec{init-value=Value:0, variable=EeIMOR_b_AuthCmd08_InFlag}, required-interface=EeIMOR_b_AuthCmd08_InFlag
    provide port EeIMOR_b_AuthCmd07_InFlag: nv-provide-com-spec{ram-block-init-value=Value:0, rom-block-init-value=Value:0, variable=EeIMOR_b_AuthCmd07_InFlag}, provided-interface=EeIMOR_b_AuthCmd07_InFlag
    require port EeIMOR_b_AuthCmd07_InFlag_Rx: nv-require-com-spec{init-value=Value:0, variable=EeIMOR_b_AuthCmd07_InFlag}, required-interface=EeIMOR_b_AuthCmd07_InFlag
    provide port EeIMOR_b_AuthCmd06_InFlag: nv-provide-com-spec{ram-block-init-value=Value:0, rom-block-init-value=Value:0, variable=EeIMOR_b_AuthCmd06_InFlag}, provided-interface=EeIMOR_b_AuthCmd06_InFlag
    require port EeIMOR_b_AuthCmd06_InFlag_Rx: nv-require-com-spec{init-value=Value:0, variable=EeIMOR_b_AuthCmd06_InFlag}, required-interface=EeIMOR_b_AuthCmd06_InFlag
    provide port EeIMOR_b_AuthCmd05_InFlag: nv-provide-com-spec{ram-block-init-value=Value:0, rom-block-init-value=Value:0, variable=EeIMOR_b_AuthCmd05_InFlag}, provided-interface=EeIMOR_b_AuthCmd05_InFlag
    require port EeIMOR_b_AuthCmd05_InFlag_Rx: nv-require-com-spec{init-value=Value:0, variable=EeIMOR_b_AuthCmd05_InFlag}, required-interface=EeIMOR_b_AuthCmd05_InFlag
    provide port EeIMOR_b_AuthCmd04_InFlag: nv-provide-com-spec{ram-block-init-value=Value:0, rom-block-init-value=Value:0, variable=EeIMOR_b_AuthCmd04_InFlag}, provided-interface=EeIMOR_b_AuthCmd04_InFlag
    require port EeIMOR_b_AuthCmd04_InFlag_Rx: nv-require-com-spec{init-value=Value:0, variable=EeIMOR_b_AuthCmd04_InFlag}, required-interface=EeIMOR_b_AuthCmd04_InFlag
    provide port EeIMOR_b_AuthCmd03_InFlag: nv-provide-com-spec{ram-block-init-value=Value:0, rom-block-init-value=Value:0, variable=EeIMOR_b_AuthCmd03_InFlag}, provided-interface=EeIMOR_b_AuthCmd03_InFlag
    require port EeIMOR_b_AuthCmd03_InFlag_Rx: nv-require-com-spec{init-value=Value:0, variable=EeIMOR_b_AuthCmd03_InFlag}, required-interface=EeIMOR_b_AuthCmd03_InFlag
    provide port EeIMOR_b_AuthCmd02_InFlag: nv-provide-com-spec{ram-block-init-value=Value:0, rom-block-init-value=Value:0, variable=EeIMOR_b_AuthCmd02_InFlag}, provided-interface=EeIMOR_b_AuthCmd02_InFlag
    require port EeIMOR_b_AuthCmd02_InFlag_Rx: nv-require-com-spec{init-value=Value:0, variable=EeIMOR_b_AuthCmd02_InFlag}, required-interface=EeIMOR_b_AuthCmd02_InFlag
    provide port EeIMOR_b_AuthCmd09_InFlag: nv-provide-com-spec{ram-block-init-value=Value:0, rom-block-init-value=Value:0, variable=EeIMOR_b_AuthCmd09_InFlag}, provided-interface=EeIMOR_b_AuthCmd09_InFlag
    require port EeIMOR_b_AuthCmd09_InFlag_Rx: nv-require-com-spec{init-value=Value:0, variable=EeIMOR_b_AuthCmd09_InFlag}, required-interface=EeIMOR_b_AuthCmd09_InFlag
    provide port EeIMOR_y_MMKey_3_Mem: nv-provide-com-spec{ram-block-init-value=Value:255, rom-block-init-value=Value:255, variable=EeIMOR_y_MMKey_3_Mem}, provided-interface=EeIMOR_y_MMKey_3_Mem
    require port EeIMOR_y_MMKey_3_Mem_Rx: nv-require-com-spec{init-value=Value:255, variable=EeIMOR_y_MMKey_3_Mem}, required-interface=EeIMOR_y_MMKey_3_Mem
    provide port EeIMOR_b_VC_VehCfg6_Stat_rec: nv-provide-com-spec{ram-block-init-value=Value:0, rom-block-init-value=Value:0, variable=EeIMOR_b_VC_VehCfg6_Stat_rec}, provided-interface=EeIMOR_b_VC_VehCfg6_Stat_rec
    require port EeIMOR_b_VC_VehCfg6_Stat_rec_Rx: nv-require-com-spec{init-value=Value:0, variable=EeIMOR_b_VC_VehCfg6_Stat_rec}, required-interface=EeIMOR_b_VC_VehCfg6_Stat_rec
    provide port EeIMOR_b_VC_VehCfg4_Stat_rec: nv-provide-com-spec{ram-block-init-value=Value:0, rom-block-init-value=Value:0, variable=EeIMOR_b_VC_VehCfg4_Stat_rec}, provided-interface=EeIMOR_b_VC_VehCfg4_Stat_rec
    require port EeIMOR_b_VC_VehCfg4_Stat_rec_Rx: nv-require-com-spec{init-value=Value:0, variable=EeIMOR_b_VC_VehCfg4_Stat_rec}, required-interface=EeIMOR_b_VC_VehCfg4_Stat_rec
    provide port EeIMOR_b_VC_VehCfg3_Stat_rec: nv-provide-com-spec{ram-block-init-value=Value:0, rom-block-init-value=Value:0, variable=EeIMOR_b_VC_VehCfg3_Stat_rec}, provided-interface=EeIMOR_b_VC_VehCfg3_Stat_rec
    require port EeIMOR_b_VC_VehCfg3_Stat_rec_Rx: nv-require-com-spec{init-value=Value:0, variable=EeIMOR_b_VC_VehCfg3_Stat_rec}, required-interface=EeIMOR_b_VC_VehCfg3_Stat_rec
    provide port EeIMOR_b_VC_VehCfg2_Stat_rec: nv-provide-com-spec{ram-block-init-value=Value:0, rom-block-init-value=Value:0, variable=EeIMOR_b_VC_VehCfg2_Stat_rec}, provided-interface=EeIMOR_b_VC_VehCfg2_Stat_rec
    require port EeIMOR_b_VC_VehCfg2_Stat_rec_Rx: nv-require-com-spec{init-value=Value:0, variable=EeIMOR_b_VC_VehCfg2_Stat_rec}, required-interface=EeIMOR_b_VC_VehCfg2_Stat_rec
    provide port EeIMOR_b_ORC_Health_rec: nv-provide-com-spec{ram-block-init-value=Value:0, rom-block-init-value=Value:0, variable=EeIMOR_b_ORC_Health_rec}, provided-interface=EeIMOR_b_ORC_Health_rec
    require port EeIMOR_b_ORC_Health_rec_Rx: nv-require-com-spec{init-value=Value:0, variable=EeIMOR_b_ORC_Health_rec}, required-interface=EeIMOR_b_ORC_Health_rec
    provide port EeIMOR_b_MMKey_6Flag: nv-provide-com-spec{ram-block-init-value=Value:0, rom-block-init-value=Value:0, variable=EeIMOR_b_MMKey_6Flag}, provided-interface=EeIMOR_b_MMKey_6Flag
    require port EeIMOR_b_MMKey_6Flag_Rx: nv-require-com-spec{init-value=Value:0, variable=EeIMOR_b_MMKey_6Flag}, required-interface=EeIMOR_b_MMKey_6Flag
    provide port EeIMOR_b_MMKey_5Flag: nv-provide-com-spec{ram-block-init-value=Value:0, rom-block-init-value=Value:0, variable=EeIMOR_b_MMKey_5Flag}, provided-interface=EeIMOR_b_MMKey_5Flag
    require port EeIMOR_b_MMKey_5Flag_Rx: nv-require-com-spec{init-value=Value:0, variable=EeIMOR_b_MMKey_5Flag}, required-interface=EeIMOR_b_MMKey_5Flag
    provide port EeIMOR_b_MMKey_4Flag: nv-provide-com-spec{ram-block-init-value=Value:0, rom-block-init-value=Value:0, variable=EeIMOR_b_MMKey_4Flag}, provided-interface=EeIMOR_b_MMKey_4Flag
    require port EeIMOR_b_MMKey_4Flag_Rx: nv-require-com-spec{init-value=Value:0, variable=EeIMOR_b_MMKey_4Flag}, required-interface=EeIMOR_b_MMKey_4Flag
    provide port EeIMOR_b_MMKey_3Flag: nv-provide-com-spec{ram-block-init-value=Value:0, rom-block-init-value=Value:0, variable=EeIMOR_b_MMKey_3Flag}, provided-interface=EeIMOR_b_MMKey_3Flag
    require port EeIMOR_b_MMKey_3Flag_Rx: nv-require-com-spec{init-value=Value:0, variable=EeIMOR_b_MMKey_3Flag}, required-interface=EeIMOR_b_MMKey_3Flag
    provide port EeIMOR_b_MMKey1org22Flag: nv-provide-com-spec{ram-block-init-value=Value:0, rom-block-init-value=Value:0, variable=EeIMOR_b_MMKey1org22Flag}, provided-interface=EeIMOR_b_MMKey1org22Flag
    require port EeIMOR_b_MMKey1org22Flag_Rx: nv-require-com-spec{init-value=Value:0, variable=EeIMOR_b_MMKey1org22Flag}, required-interface=EeIMOR_b_MMKey1org22Flag
    provide port EeIMOR_b_MMKey1org21Flag: nv-provide-com-spec{ram-block-init-value=Value:0, rom-block-init-value=Value:0, variable=EeIMOR_b_MMKey1org21Flag}, provided-interface=EeIMOR_b_MMKey1org21Flag
    require port EeIMOR_b_MMKey1org21Flag_Rx: nv-require-com-spec{init-value=Value:0, variable=EeIMOR_b_MMKey1org21Flag}, required-interface=EeIMOR_b_MMKey1org21Flag
    provide port EeIMOR_b_MKeyStrToE2: nv-provide-com-spec{ram-block-init-value=Value:0, rom-block-init-value=Value:0, variable=EeIMOR_b_MKeyStrToE2}, provided-interface=EeIMOR_b_MKeyStrToE2
    require port EeIMOR_b_MKeyStrToE2_Rx: nv-require-com-spec{init-value=Value:0, variable=EeIMOR_b_MKeyStrToE2}, required-interface=EeIMOR_b_MKeyStrToE2
    provide port EeIMOR_b_ImmoAuthValid_Mem: nv-provide-com-spec{ram-block-init-value=Value:0, rom-block-init-value=Value:0, variable=EeIMOR_b_ImmoAuthValid_Mem}, provided-interface=EeIMOR_b_ImmoAuthValid_Mem
    require port EeIMOR_b_ImmoAuthValid_Mem_Rx: nv-require-com-spec{init-value=Value:0, variable=EeIMOR_b_ImmoAuthValid_Mem}, required-interface=EeIMOR_b_ImmoAuthValid_Mem
    provide port EeIMOR_b_ImmoAuthValid_ECMMem: nv-provide-com-spec{ram-block-init-value=Value:0, rom-block-init-value=Value:0, variable=EeIMOR_b_ImmoAuthValid_ECMMem}, provided-interface=EeIMOR_b_ImmoAuthValid_ECMMem
    require port EeIMOR_b_ImmoAuthValid_ECMMem_Rx: nv-require-com-spec{init-value=Value:0, variable=EeIMOR_b_ImmoAuthValid_ECMMem}, required-interface=EeIMOR_b_ImmoAuthValid_ECMMem
    provide port EeIMOR_b_CodeRecCmplt_Mem: nv-provide-com-spec{ram-block-init-value=Value:0, rom-block-init-value=Value:0, variable=EeIMOR_b_CodeRecCmplt_Mem}, provided-interface=EeIMOR_b_CodeRecCmplt_Mem
    require port EeIMOR_b_CodeRecCmplt_Mem_Rx: nv-require-com-spec{init-value=Value:0, variable=EeIMOR_b_CodeRecCmplt_Mem}, required-interface=EeIMOR_b_CodeRecCmplt_Mem
    provide port EeIMOR_b_CntrlEncdResFlag: nv-provide-com-spec{ram-block-init-value=Value:0, rom-block-init-value=Value:0, variable=EeIMOR_b_CntrlEncdResFlag}, provided-interface=EeIMOR_b_CntrlEncdResFlag
    require port EeIMOR_b_CntrlEncdResFlag_Rx: nv-require-com-spec{init-value=Value:0, variable=EeIMOR_b_CntrlEncdResFlag}, required-interface=EeIMOR_b_CntrlEncdResFlag
    provide port EeIMOR_b_AuthCmdCntrlEncdRespFlag: nv-provide-com-spec{ram-block-init-value=Value:0, rom-block-init-value=Value:0, variable=EeIMOR_b_AuthCmdCntrlEncdRespFlag}, provided-interface=EeIMOR_b_AuthCmdCntrlEncdRespFlag
    require port EeIMOR_b_AuthCmdCntrlEncdRespFlag_Rx: nv-require-com-spec{init-value=Value:0, variable=EeIMOR_b_AuthCmdCntrlEncdRespFlag}, required-interface=EeIMOR_b_AuthCmdCntrlEncdRespFlag
    provide port EeIMOR_b_AuthCmd15_InFlag: nv-provide-com-spec{ram-block-init-value=Value:0, rom-block-init-value=Value:0, variable=EeIMOR_b_AuthCmd15_InFlag}, provided-interface=EeIMOR_b_AuthCmd15_InFlag
    require port EeIMOR_b_AuthCmd15_InFlag_Rx: nv-require-com-spec{init-value=Value:0, variable=EeIMOR_b_AuthCmd15_InFlag}, required-interface=EeIMOR_b_AuthCmd15_InFlag
    provide port EeIMOR_b_AuthCmd14_InFlag: nv-provide-com-spec{ram-block-init-value=Value:0, rom-block-init-value=Value:0, variable=EeIMOR_b_AuthCmd14_InFlag}, provided-interface=EeIMOR_b_AuthCmd14_InFlag
    require port EeIMOR_b_AuthCmd14_InFlag_Rx: nv-require-com-spec{init-value=Value:0, variable=EeIMOR_b_AuthCmd14_InFlag}, required-interface=EeIMOR_b_AuthCmd14_InFlag
    provide port EeIMOR_b_AuthCmd13_InFlag: nv-provide-com-spec{ram-block-init-value=Value:0, rom-block-init-value=Value:0, variable=EeIMOR_b_AuthCmd13_InFlag}, provided-interface=EeIMOR_b_AuthCmd13_InFlag
    require port EeIMOR_b_AuthCmd13_InFlag_Rx: nv-require-com-spec{init-value=Value:0, variable=EeIMOR_b_AuthCmd13_InFlag}, required-interface=EeIMOR_b_AuthCmd13_InFlag
    provide port EeIMOR_b_AuthCmd12_InFlag: nv-provide-com-spec{ram-block-init-value=Value:0, rom-block-init-value=Value:0, variable=EeIMOR_b_AuthCmd12_InFlag}, provided-interface=EeIMOR_b_AuthCmd12_InFlag
    require port EeIMOR_b_AuthCmd12_InFlag_Rx: nv-require-com-spec{init-value=Value:0, variable=EeIMOR_b_AuthCmd12_InFlag}, required-interface=EeIMOR_b_AuthCmd12_InFlag
    provide port EeIMOR_b_AuthCmd11_InFlag: nv-provide-com-spec{ram-block-init-value=Value:0, rom-block-init-value=Value:0, variable=EeIMOR_b_AuthCmd11_InFlag}, provided-interface=EeIMOR_b_AuthCmd11_InFlag
    require port EeIMOR_b_AuthCmd11_InFlag_Rx: nv-require-com-spec{init-value=Value:0, variable=EeIMOR_b_AuthCmd11_InFlag}, required-interface=EeIMOR_b_AuthCmd11_InFlag
    provide port EeIMOR_b_AuthCmd10_InFlag: nv-provide-com-spec{ram-block-init-value=Value:0, rom-block-init-value=Value:0, variable=EeIMOR_b_AuthCmd10_InFlag}, provided-interface=EeIMOR_b_AuthCmd10_InFlag
    require port EeIMOR_b_AuthCmd10_InFlag_Rx: nv-require-com-spec{init-value=Value:0, variable=EeIMOR_b_AuthCmd10_InFlag}, required-interface=EeIMOR_b_AuthCmd10_InFlag
    provide port EeHPMR_b_ORC_LOCFA: nv-provide-com-spec{ram-block-init-value=Value:0, rom-block-init-value=Value:0, variable=EeHPMR_b_ORC_LOCFA}, provided-interface=EeHPMR_b_ORC_LOCFA
    require port EeHPMR_b_ORC_LOCFA_Rx: nv-require-com-spec{init-value=Value:0, variable=EeHPMR_b_ORC_LOCFA}, required-interface=EeHPMR_b_ORC_LOCFA
    provide port EeHMIR_e_HEV_LMP_RQ: nv-provide-com-spec{ram-block-init-value=Value:255, rom-block-init-value=Value:255, variable=EeHMIR_e_HEV_LMP_RQ}, provided-interface=EeHMIR_e_HEV_LMP_RQ
    require port EeHMIR_e_HEV_LMP_RQ_Rx: nv-require-com-spec{init-value=Value:255, variable=EeHMIR_e_HEV_LMP_RQ}, required-interface=EeHMIR_e_HEV_LMP_RQ
    provide port EePWDR_b_DAPFA_OpenCntctr: nv-provide-com-spec{ram-block-init-value=Value:0, rom-block-init-value=Value:0, variable=EePWDR_b_DAPFA_OpenCntctr}, provided-interface=EePWDR_b_DAPFA_OpenCntctr
    require port EePWDR_b_DAPFA_OpenCntctr_Rx: nv-require-com-spec{init-value=Value:0, variable=EePWDR_b_DAPFA_OpenCntctr}, required-interface=EePWDR_b_DAPFA_OpenCntctr
    provide port EePWDR_Cnt_WarmupCycle: nv-provide-com-spec{ram-block-init-value=Value:0, rom-block-init-value=Value:0, variable=EePWDR_Cnt_WarmupCycle}, provided-interface=EePWDR_Cnt_WarmupCycle
    require port EePWDR_Cnt_WarmupCycle_Rx: nv-require-com-spec{init-value=Value:0, variable=EePWDR_Cnt_WarmupCycle}, required-interface=EePWDR_Cnt_WarmupCycle
    provide port EePWDR_Cnt_DAP_FA_KeyCylCnt: nv-provide-com-spec{ram-block-init-value=Value:0, rom-block-init-value=Value:0, variable=EePWDR_Cnt_DAP_FA_KeyCylCnt}, provided-interface=EePWDR_Cnt_DAP_FA_KeyCylCnt
    require port EePWDR_Cnt_DAP_FA_KeyCylCnt_Rx: nv-require-com-spec{init-value=Value:0, variable=EePWDR_Cnt_DAP_FA_KeyCylCnt}, required-interface=EePWDR_Cnt_DAP_FA_KeyCylCnt
    provide port EeHCDR_b_InitDiag_Pass_Prev: nv-provide-com-spec{ram-block-init-value=Value:0, rom-block-init-value=Value:0, variable=EeHCDR_b_InitDiag_Pass_Prev}, provided-interface=EeHCDR_b_InitDiag_Pass_Prev
    require port EeHCDR_b_InitDiag_Pass_Prev_Rx: nv-require-com-spec{init-value=Value:0, variable=EeHCDR_b_InitDiag_Pass_Prev}, required-interface=EeHCDR_b_InitDiag_Pass_Prev
    provide port EeERER_e_TrailerConnectionSts: nv-provide-com-spec{ram-block-init-value=Value:0, rom-block-init-value=Value:0, variable=EeERER_e_TrailerConnectionSts}, provided-interface=EeERER_e_TrailerConnectionSts
    require port EeERER_e_TrailerConnectionSts_Rx: nv-require-com-spec{init-value=Value:0, variable=EeERER_e_TrailerConnectionSts}, required-interface=EeERER_e_TrailerConnectionSts
    provide port EeERER_b_EEPROM_WhperKM: nv-provide-com-spec{ram-block-init-value=Value:0, rom-block-init-value=Value:0, variable=EeERER_b_EEPROM_WhperKM}, provided-interface=EeERER_b_EEPROM_WhperKM
    require port EeERER_b_EEPROM_WhperKM_Rx: nv-require-com-spec{init-value=Value:0, variable=EeERER_b_EEPROM_WhperKM}, required-interface=EeERER_b_EEPROM_WhperKM
    provide port EeERER_b_EEPROM_EstRange: nv-provide-com-spec{ram-block-init-value=Value:0, rom-block-init-value=Value:0, variable=EeERER_b_EEPROM_EstRange}, provided-interface=EeERER_b_EEPROM_EstRange
    require port EeERER_b_EEPROM_EstRange_Rx: nv-require-com-spec{init-value=Value:0, variable=EeERER_b_EEPROM_EstRange}, required-interface=EeERER_b_EEPROM_EstRange
    provide port EEeERER_e_TrailerConnectionSts: nv-provide-com-spec{ram-block-init-value=Value:0, rom-block-init-value=Value:0, variable=EEeERER_e_TrailerConnectionSts}, provided-interface=EEeERER_e_TrailerConnectionSts
    require port EEeERER_e_TrailerConnectionSts_Rx: nv-require-com-spec{init-value=Value:0, variable=EEeERER_e_TrailerConnectionSts}, required-interface=EEeERER_e_TrailerConnectionSts
    provide port EeIMOR_y_MMKey1org21_Mem: nv-provide-com-spec{ram-block-init-value=Value:255, rom-block-init-value=Value:255, variable=EeIMOR_y_MMKey1org21_Mem}, provided-interface=EeIMOR_y_MMKey1org21_Mem
    require port EeIMOR_y_MMKey1org21_Mem_Rx: nv-require-com-spec{init-value=Value:255, variable=EeIMOR_y_MMKey1org21_Mem}, required-interface=EeIMOR_y_MMKey1org21_Mem
    provide port EeIMOR_b_AuthCmd01_InFlag: nv-provide-com-spec{ram-block-init-value=Value:0, rom-block-init-value=Value:0, variable=EeIMOR_b_AuthCmd01_InFlag}, provided-interface=EeIMOR_b_AuthCmd01_InFlag
    require port EeIMOR_b_AuthCmd01_InFlag_Rx: nv-require-com-spec{init-value=Value:0, variable=EeIMOR_b_AuthCmd01_InFlag}, required-interface=EeIMOR_b_AuthCmd01_InFlag
    provide port EeIMOR_b_AuthCmd00_InFlag: nv-provide-com-spec{ram-block-init-value=Value:0, rom-block-init-value=Value:0, variable=EeIMOR_b_AuthCmd00_InFlag}, provided-interface=EeIMOR_b_AuthCmd00_InFlag
    require port EeIMOR_b_AuthCmd00_InFlag_Rx: nv-require-com-spec{init-value=Value:0, variable=EeIMOR_b_AuthCmd00_InFlag}, required-interface=EeIMOR_b_AuthCmd00_InFlag
    provide port EeIMOR_y_MMKey_4_Mem: nv-provide-com-spec{ram-block-init-value=Value:255, rom-block-init-value=Value:255, variable=EeIMOR_y_MMKey_4_Mem}, provided-interface=EeIMOR_y_MMKey_4_Mem
    require port EeIMOR_y_MMKey_4_Mem_Rx: nv-require-com-spec{init-value=Value:255, variable=EeIMOR_y_MMKey_4_Mem}, required-interface=EeIMOR_y_MMKey_4_Mem
    provide port EeIMOR_y_MMKey_5_Mem: nv-provide-com-spec{ram-block-init-value=Value:255, rom-block-init-value=Value:255, variable=EeIMOR_y_MMKey_5_Mem}, provided-interface=EeIMOR_y_MMKey_5_Mem
    require port EeIMOR_y_MMKey_5_Mem_Rx: nv-require-com-spec{init-value=Value:255, variable=EeIMOR_y_MMKey_5_Mem}, required-interface=EeIMOR_y_MMKey_5_Mem
    provide port EeHVTR_b_OpnReq_SrvcProc1320: nv-provide-com-spec{ram-block-init-value=Value:0, rom-block-init-value=Value:0, variable=EeHVTR_b_OpnReq_SrvcProc1320}, provided-interface=EeHVTR_b_OpnReq_SrvcProc1320
    require port EeHVTR_b_OpnReq_SrvcProc1320_Rx: nv-require-com-spec{init-value=Value:0, variable=EeHVTR_b_OpnReq_SrvcProc1320}, required-interface=EeHVTR_b_OpnReq_SrvcProc1320
    provide port EeIMOR_y_MMKey_6_Mem: nv-provide-com-spec{ram-block-init-value=Value:255, rom-block-init-value=Value:255, variable=EeIMOR_y_MMKey_6_Mem}, provided-interface=EeIMOR_y_MMKey_6_Mem
    require port EeIMOR_y_MMKey_6_Mem_Rx: nv-require-com-spec{init-value=Value:255, variable=EeIMOR_y_MMKey_6_Mem}, required-interface=EeIMOR_y_MMKey_6_Mem
    provide port EePWDR_y_DID_B524: nv-provide-com-spec{ram-block-init-value=Value:0, rom-block-init-value=Value:0, variable=EePWDR_y_DID_B524}, provided-interface=EePWDR_y_DID_B524
    require port EePWDR_y_DID_B524_Rx: nv-require-com-spec{init-value=Value:0, variable=EePWDR_y_DID_B524}, required-interface=EePWDR_y_DID_B524
    provide port EeAADR_Cnt_AAD_PSACntrLastCal: nv-provide-com-spec{ram-block-init-value=Value:0, rom-block-init-value=Value:0, variable=EeAADR_Cnt_AAD_PSACntrLastCal}, provided-interface=EeAADR_Cnt_AAD_PSACntrLastCal
    require port EeAADR_Cnt_AAD_PSACntrLastCal_Rx: nv-require-com-spec{init-value=Value:0, variable=EeAADR_Cnt_AAD_PSACntrLastCal}, required-interface=EeAADR_Cnt_AAD_PSACntrLastCal
    provide port BeFWDR_r_Axle_Ratio: nv-provide-com-spec{ram-block-init-value=Value:4294967295, rom-block-init-value=Value:4294967295, variable=BeFWDR_r_Axle_Ratio}, provided-interface=BeFWDR_r_Axle_Ratio
    require port BeFWDR_r_Axle_Ratio_Rx: nv-require-com-spec{init-value=Value:4294967295, variable=BeFWDR_r_Axle_Ratio}, required-interface=BeFWDR_r_Axle_Ratio
    provide port BeFWDR_r_Tcase_Hi_Ratio: nv-provide-com-spec{ram-block-init-value=Value:4294967295, rom-block-init-value=Value:4294967295, variable=BeFWDR_r_Tcase_Hi_Ratio}, provided-interface=BeFWDR_r_Tcase_Hi_Ratio
    require port BeFWDR_r_Tcase_Hi_Ratio_Rx: nv-require-com-spec{init-value=Value:4294967295, variable=BeFWDR_r_Tcase_Hi_Ratio}, required-interface=BeFWDR_r_Tcase_Hi_Ratio
    provide port BeFWDR_r_Tcase_Low_Ratio: nv-provide-com-spec{ram-block-init-value=Value:4294967295, rom-block-init-value=Value:4294967295, variable=BeFWDR_r_Tcase_Low_Ratio}, provided-interface=BeFWDR_r_Tcase_Low_Ratio
    require port BeFWDR_r_Tcase_Low_Ratio_Rx: nv-require-com-spec{init-value=Value:4294967295, variable=BeFWDR_r_Tcase_Low_Ratio}, required-interface=BeFWDR_r_Tcase_Low_Ratio
    provide port BeRTMR_g_BSGRestartRsn: nv-provide-com-spec{ram-block-init-value=Value:0, rom-block-init-value=Value:0, variable=BeRTMR_g_BSGRestartRsn}, provided-interface=BeRTMR_g_BSGRestartRsn
    require port BeRTMR_g_BSGRestartRsn_Rx: nv-require-com-spec{init-value=Value:0, variable=BeRTMR_g_BSGRestartRsn}, required-interface=BeRTMR_g_BSGRestartRsn
    provide port BeTRGR_d_IP_PRNDLTestFlags: nv-provide-com-spec{ram-block-init-value=Value:0, rom-block-init-value=Value:0, variable=BeTRGR_d_IP_PRNDLTestFlags}, provided-interface=BeTRGR_d_IP_PRNDLTestFlags
    require port BeTRGR_d_IP_PRNDLTestFlags_Rx: nv-require-com-spec{init-value=Value:0, variable=BeTRGR_d_IP_PRNDLTestFlags}, required-interface=BeTRGR_d_IP_PRNDLTestFlags
    provide port BeFWDR_e_Tcase_Stat: nv-provide-com-spec{ram-block-init-value=Value:32767, rom-block-init-value=Value:32767, variable=BeFWDR_e_Tcase_Stat}, provided-interface=BeFWDR_e_Tcase_Stat
    require port BeFWDR_e_Tcase_Stat_Rx: nv-require-com-spec{init-value=Value:32767, variable=BeFWDR_e_Tcase_Stat}, required-interface=BeFWDR_e_Tcase_Stat
    provide port BeRTMR_y_ClutchLrnTstCndtnCheck3_PID: nv-provide-com-spec{ram-block-init-value=Value:0, rom-block-init-value=Value:0, variable=BeRTMR_y_ClutchLrnTstCndtnCheck3_PID}, provided-interface=BeRTMR_y_ClutchLrnTstCndtnCheck3_PID
    require port BeRTMR_y_ClutchLrnTstCndtnCheck3_PID_Rx: nv-require-com-spec{init-value=Value:0, variable=BeRTMR_y_ClutchLrnTstCndtnCheck3_PID}, required-interface=BeRTMR_y_ClutchLrnTstCndtnCheck3_PID
    provide port BeRTMR_y_ElecOnlyTstCndtnCheck1_PID: nv-provide-com-spec{ram-block-init-value=Value:0, rom-block-init-value=Value:0, variable=BeRTMR_y_ElecOnlyTstCndtnCheck1_PID}, provided-interface=BeRTMR_y_ElecOnlyTstCndtnCheck1_PID
    require port BeRTMR_y_ElecOnlyTstCndtnCheck1_PID_Rx: nv-require-com-spec{init-value=Value:0, variable=BeRTMR_y_ElecOnlyTstCndtnCheck1_PID}, required-interface=BeRTMR_y_ElecOnlyTstCndtnCheck1_PID
    provide port BeRTMR_y_ElecOnlyTstCndtnCheck2_PID: nv-provide-com-spec{ram-block-init-value=Value:0, rom-block-init-value=Value:0, variable=BeRTMR_y_ElecOnlyTstCndtnCheck2_PID}, provided-interface=BeRTMR_y_ElecOnlyTstCndtnCheck2_PID
    require port BeRTMR_y_ElecOnlyTstCndtnCheck2_PID_Rx: nv-require-com-spec{init-value=Value:0, variable=BeRTMR_y_ElecOnlyTstCndtnCheck2_PID}, required-interface=BeRTMR_y_ElecOnlyTstCndtnCheck2_PID
    provide port BeRTMR_y_ReslvrOfsLrnCndtnCheck3_PID: nv-provide-com-spec{ram-block-init-value=Value:0, rom-block-init-value=Value:0, variable=BeRTMR_y_ReslvrOfsLrnCndtnCheck3_PID}, provided-interface=BeRTMR_y_ReslvrOfsLrnCndtnCheck3_PID
    require port BeRTMR_y_ReslvrOfsLrnCndtnCheck3_PID_Rx: nv-require-com-spec{init-value=Value:0, variable=BeRTMR_y_ReslvrOfsLrnCndtnCheck3_PID}, required-interface=BeRTMR_y_ReslvrOfsLrnCndtnCheck3_PID
    provide port BeRTMR_y_ReslvrOfsLrnFaultStatus3_PID: nv-provide-com-spec{ram-block-init-value=Value:0, rom-block-init-value=Value:0, variable=BeRTMR_y_ReslvrOfsLrnFaultStatus3_PID}, provided-interface=BeRTMR_y_ReslvrOfsLrnFaultStatus3_PID
    require port BeRTMR_y_ReslvrOfsLrnFaultStatus3_PID_Rx: nv-require-com-spec{init-value=Value:0, variable=BeRTMR_y_ReslvrOfsLrnFaultStatus3_PID}, required-interface=BeRTMR_y_ReslvrOfsLrnFaultStatus3_PID
    provide port BeRTMR_y_ReslvrOfsLrnFaultStatus4_PID: nv-provide-com-spec{ram-block-init-value=Value:0, rom-block-init-value=Value:0, variable=BeRTMR_y_ReslvrOfsLrnFaultStatus4_PID}, provided-interface=BeRTMR_y_ReslvrOfsLrnFaultStatus4_PID
    require port BeRTMR_y_ReslvrOfsLrnFaultStatus4_PID_Rx: nv-require-com-spec{init-value=Value:0, variable=BeRTMR_y_ReslvrOfsLrnFaultStatus4_PID}, required-interface=BeRTMR_y_ReslvrOfsLrnFaultStatus4_PID
    provide port BeRTMR_y_ReslvrOfsLrnFaultStatus5_PID: nv-provide-com-spec{ram-block-init-value=Value:0, rom-block-init-value=Value:0, variable=BeRTMR_y_ReslvrOfsLrnFaultStatus5_PID}, provided-interface=BeRTMR_y_ReslvrOfsLrnFaultStatus5_PID
    require port BeRTMR_y_ReslvrOfsLrnFaultStatus5_PID_Rx: nv-require-com-spec{init-value=Value:0, variable=BeRTMR_y_ReslvrOfsLrnFaultStatus5_PID}, required-interface=BeRTMR_y_ReslvrOfsLrnFaultStatus5_PID
    provide port BeRTMR_y_ClutchLrnTstCndtnCheck2_PID: nv-provide-com-spec{ram-block-init-value=Value:0, rom-block-init-value=Value:0, variable=BeRTMR_y_ClutchLrnTstCndtnCheck2_PID}, provided-interface=BeRTMR_y_ClutchLrnTstCndtnCheck2_PID
    require port BeRTMR_y_ClutchLrnTstCndtnCheck2_PID_Rx: nv-require-com-spec{init-value=Value:0, variable=BeRTMR_y_ClutchLrnTstCndtnCheck2_PID}, required-interface=BeRTMR_y_ClutchLrnTstCndtnCheck2_PID
    provide port BeRTMR_y_ClutchLrnTstCndtnCheck1_PID: nv-provide-com-spec{ram-block-init-value=Value:0, rom-block-init-value=Value:0, variable=BeRTMR_y_ClutchLrnTstCndtnCheck1_PID}, provided-interface=BeRTMR_y_ClutchLrnTstCndtnCheck1_PID
    require port BeRTMR_y_ClutchLrnTstCndtnCheck1_PID_Rx: nv-require-com-spec{init-value=Value:0, variable=BeRTMR_y_ClutchLrnTstCndtnCheck1_PID}, required-interface=BeRTMR_y_ClutchLrnTstCndtnCheck1_PID
    provide port BeRTMR_y_ClutchLrnTestStatus_PID: nv-provide-com-spec{ram-block-init-value=Value:0, rom-block-init-value=Value:0, variable=BeRTMR_y_ClutchLrnTestStatus_PID}, provided-interface=BeRTMR_y_ClutchLrnTestStatus_PID
    require port BeRTMR_y_ClutchLrnTestStatus_PID_Rx: nv-require-com-spec{init-value=Value:0, variable=BeRTMR_y_ClutchLrnTestStatus_PID}, required-interface=BeRTMR_y_ClutchLrnTestStatus_PID
    provide port BeHSWR_b_ECMHdStatSaved: nv-provide-com-spec{ram-block-init-value=Value:1, rom-block-init-value=Value:1, variable=BeHSWR_b_ECMHdStatSaved}, provided-interface=BeHSWR_b_ECMHdStatSaved
    require port BeHSWR_b_ECMHdStatSaved_Rx: nv-require-com-spec{init-value=Value:1, variable=BeHSWR_b_ECMHdStatSaved}, required-interface=BeHSWR_b_ECMHdStatSaved
    provide port DeESMR_P_HV_BatChrgPwrLTArb: nv-provide-com-spec{ram-block-init-value=Value:-26, rom-block-init-value=Value:-26, variable=DeESMR_P_HV_BatChrgPwrLTArb}, provided-interface=DeESMR_P_HV_BatChrgPwrLTArb
    require port DeESMR_P_HV_BatChrgPwrLTArb_Rx: nv-require-com-spec{init-value=Value:-26, variable=DeESMR_P_HV_BatChrgPwrLTArb}, required-interface=DeESMR_P_HV_BatChrgPwrLTArb
    provide port DeESMR_P_HV_BatChrgPwrSTArb: nv-provide-com-spec{ram-block-init-value=Value:-31, rom-block-init-value=Value:-31, variable=DeESMR_P_HV_BatChrgPwrSTArb}, provided-interface=DeESMR_P_HV_BatChrgPwrSTArb
    require port DeESMR_P_HV_BatChrgPwrSTArb_Rx: nv-require-com-spec{init-value=Value:-31, variable=DeESMR_P_HV_BatChrgPwrSTArb}, required-interface=DeESMR_P_HV_BatChrgPwrSTArb
    provide port DeESMR_P_HV_BatDschrgPwrLTArb: nv-provide-com-spec{ram-block-init-value=Value:31, rom-block-init-value=Value:31, variable=DeESMR_P_HV_BatDschrgPwrLTArb}, provided-interface=DeESMR_P_HV_BatDschrgPwrLTArb
    require port DeESMR_P_HV_BatDschrgPwrLTArb_Rx: nv-require-com-spec{init-value=Value:31, variable=DeESMR_P_HV_BatDschrgPwrLTArb}, required-interface=DeESMR_P_HV_BatDschrgPwrLTArb
    provide port DeESMC_P_AccumChrgEnergy: nv-provide-com-spec{ram-block-init-value=Value:0, rom-block-init-value=Value:0, variable=DeESMC_P_AccumChrgEnergy}, provided-interface=DeESMC_P_AccumChrgEnergy
    require port DeESMC_P_AccumChrgEnergy_Rx: nv-require-com-spec{init-value=Value:0, variable=DeESMC_P_AccumChrgEnergy}, required-interface=DeESMC_P_AccumChrgEnergy
    provide port DeESMC_P_AccumDisChgEnergy: nv-provide-com-spec{ram-block-init-value=Value:0, rom-block-init-value=Value:0, variable=DeESMC_P_AccumDisChgEnergy}, provided-interface=DeESMC_P_AccumDisChgEnergy
    require port DeESMC_P_AccumDisChgEnergy_Rx: nv-require-com-spec{init-value=Value:0, variable=DeESMC_P_AccumDisChgEnergy}, required-interface=DeESMC_P_AccumDisChgEnergy
    provide port DeESMC_I_AccumDisChrgCurr: nv-provide-com-spec{ram-block-init-value=Value:0, rom-block-init-value=Value:0, variable=DeESMC_I_AccumDisChrgCurr}, provided-interface=DeESMC_I_AccumDisChrgCurr
    require port DeESMC_I_AccumDisChrgCurr_Rx: nv-require-com-spec{init-value=Value:0, variable=DeESMC_I_AccumDisChrgCurr}, required-interface=DeESMC_I_AccumDisChrgCurr
    provide port DeESMC_I_AccumChrgCurr: nv-provide-com-spec{ram-block-init-value=Value:0, rom-block-init-value=Value:0, variable=DeESMC_I_AccumChrgCurr}, provided-interface=DeESMC_I_AccumChrgCurr
    require port DeESMC_I_AccumChrgCurr_Rx: nv-require-com-spec{init-value=Value:0, variable=DeESMC_I_AccumChrgCurr}, required-interface=DeESMC_I_AccumChrgCurr
    provide port DeESMR_P_HV_BatDschrgPwrSTArb: nv-provide-com-spec{ram-block-init-value=Value:36, rom-block-init-value=Value:36, variable=DeESMR_P_HV_BatDschrgPwrSTArb}, provided-interface=DeESMR_P_HV_BatDschrgPwrSTArb
    require port DeESMR_P_HV_BatDschrgPwrSTArb_Rx: nv-require-com-spec{init-value=Value:36, variable=DeESMR_P_HV_BatDschrgPwrSTArb}, required-interface=DeESMR_P_HV_BatDschrgPwrSTArb
    provide port DeBPCR_P_HV_BatChrgPwrET: nv-provide-com-spec{ram-block-init-value=Value:0, rom-block-init-value=Value:0, variable=DeBPCR_P_HV_BatChrgPwrET}, provided-interface=DeBPCR_P_HV_BatChrgPwrET
    require port DeBPCR_P_HV_BatChrgPwrET_Rx: nv-require-com-spec{init-value=Value:0, variable=DeBPCR_P_HV_BatChrgPwrET}, required-interface=DeBPCR_P_HV_BatChrgPwrET
    provide port DeBPCR_P_HV_BatChrgPwrST: nv-provide-com-spec{ram-block-init-value=Value:0, rom-block-init-value=Value:0, variable=DeBPCR_P_HV_BatChrgPwrST}, provided-interface=DeBPCR_P_HV_BatChrgPwrST
    require port DeBPCR_P_HV_BatChrgPwrST_Rx: nv-require-com-spec{init-value=Value:0, variable=DeBPCR_P_HV_BatChrgPwrST}, required-interface=DeBPCR_P_HV_BatChrgPwrST
    provide port DeBPCR_P_HV_BatDschrgPwrET: nv-provide-com-spec{ram-block-init-value=Value:0, rom-block-init-value=Value:0, variable=DeBPCR_P_HV_BatDschrgPwrET}, provided-interface=DeBPCR_P_HV_BatDschrgPwrET
    require port DeBPCR_P_HV_BatDschrgPwrET_Rx: nv-require-com-spec{init-value=Value:0, variable=DeBPCR_P_HV_BatDschrgPwrET}, required-interface=DeBPCR_P_HV_BatDschrgPwrET
    provide port DeBPCR_P_HV_BatDschrgPwrLT: nv-provide-com-spec{ram-block-init-value=Value:0, rom-block-init-value=Value:0, variable=DeBPCR_P_HV_BatDschrgPwrLT}, provided-interface=DeBPCR_P_HV_BatDschrgPwrLT
    require port DeBPCR_P_HV_BatDschrgPwrLT_Rx: nv-require-com-spec{init-value=Value:0, variable=DeBPCR_P_HV_BatDschrgPwrLT}, required-interface=DeBPCR_P_HV_BatDschrgPwrLT
    provide port DeBPCR_Pct_HV_BatSOC_DS: nv-provide-com-spec{ram-block-init-value=Value:0, rom-block-init-value=Value:0, variable=DeBPCR_Pct_HV_BatSOC_DS}, provided-interface=DeBPCR_Pct_HV_BatSOC_DS
    require port DeBPCR_Pct_HV_BatSOC_DS_Rx: nv-require-com-spec{init-value=Value:0, variable=DeBPCR_Pct_HV_BatSOC_DS}, required-interface=DeBPCR_Pct_HV_BatSOC_DS
    provide port DeBPCR_P_HV_BatChrgPwrLT: nv-provide-com-spec{ram-block-init-value=Value:0, rom-block-init-value=Value:0, variable=DeBPCR_P_HV_BatChrgPwrLT}, provided-interface=DeBPCR_P_HV_BatChrgPwrLT
    require port DeBPCR_P_HV_BatChrgPwrLT_Rx: nv-require-com-spec{init-value=Value:0, variable=DeBPCR_P_HV_BatChrgPwrLT}, required-interface=DeBPCR_P_HV_BatChrgPwrLT
    provide port DeBPCR_P_HV_BatDschrgPwrST: nv-provide-com-spec{ram-block-init-value=Value:0, rom-block-init-value=Value:0, variable=DeBPCR_P_HV_BatDschrgPwrST}, provided-interface=DeBPCR_P_HV_BatDschrgPwrST
    require port DeBPCR_P_HV_BatDschrgPwrST_Rx: nv-require-com-spec{init-value=Value:0, variable=DeBPCR_P_HV_BatDschrgPwrST}, required-interface=DeBPCR_P_HV_BatDschrgPwrST
    provide port FeSCPR_g_ChrgNowMaxTimetoPlugin: nv-provide-com-spec{ram-block-init-value=Value:0, rom-block-init-value=Value:0, variable=FeSCPR_g_ChrgNowMaxTimetoPlugin}, provided-interface=FeSCPR_g_ChrgNowMaxTimetoPlugin
    require port FeSCPR_g_ChrgNowMaxTimetoPlugin_Rx: nv-require-com-spec{init-value=Value:0, variable=FeSCPR_g_ChrgNowMaxTimetoPlugin}, required-interface=FeSCPR_g_ChrgNowMaxTimetoPlugin
    provide port FeSCPR_T_Sch2CP_DepTemp: nv-provide-com-spec{ram-block-init-value=Value:0, rom-block-init-value=Value:0, variable=FeSCPR_T_Sch2CP_DepTemp}, provided-interface=FeSCPR_T_Sch2CP_DepTemp
    require port FeSCPR_T_Sch2CP_DepTemp_Rx: nv-require-com-spec{init-value=Value:0, variable=FeSCPR_T_Sch2CP_DepTemp}, required-interface=FeSCPR_T_Sch2CP_DepTemp
    provide port FeSCPR_T_Sch1CP_DepTemp: nv-provide-com-spec{ram-block-init-value=Value:0, rom-block-init-value=Value:0, variable=FeSCPR_T_Sch1CP_DepTemp}, provided-interface=FeSCPR_T_Sch1CP_DepTemp
    require port FeSCPR_T_Sch1CP_DepTemp_Rx: nv-require-com-spec{init-value=Value:0, variable=FeSCPR_T_Sch1CP_DepTemp}, required-interface=FeSCPR_T_Sch1CP_DepTemp
    provide port FeSCPR_e_Sch2CP_DepMin: nv-provide-com-spec{ram-block-init-value=Value:0, rom-block-init-value=Value:0, variable=FeSCPR_e_Sch2CP_DepMin}, provided-interface=FeSCPR_e_Sch2CP_DepMin
    require port FeSCPR_e_Sch2CP_DepMin_Rx: nv-require-com-spec{init-value=Value:0, variable=FeSCPR_e_Sch2CP_DepMin}, required-interface=FeSCPR_e_Sch2CP_DepMin
    provide port FeSCPR_e_Sch2CP_DepHr: nv-provide-com-spec{ram-block-init-value=Value:0, rom-block-init-value=Value:0, variable=FeSCPR_e_Sch2CP_DepHr}, provided-interface=FeSCPR_e_Sch2CP_DepHr
    require port FeSCPR_e_Sch2CP_DepHr_Rx: nv-require-com-spec{init-value=Value:0, variable=FeSCPR_e_Sch2CP_DepHr}, required-interface=FeSCPR_e_Sch2CP_DepHr
    provide port FeSCPR_e_Sch2CH_StrtMin: nv-provide-com-spec{ram-block-init-value=Value:0, rom-block-init-value=Value:0, variable=FeSCPR_e_Sch2CH_StrtMin}, provided-interface=FeSCPR_e_Sch2CH_StrtMin
    require port FeSCPR_e_Sch2CH_StrtMin_Rx: nv-require-com-spec{init-value=Value:0, variable=FeSCPR_e_Sch2CH_StrtMin}, required-interface=FeSCPR_e_Sch2CH_StrtMin
    provide port FeSCPR_e_Sch2CH_StrtHr: nv-provide-com-spec{ram-block-init-value=Value:0, rom-block-init-value=Value:0, variable=FeSCPR_e_Sch2CH_StrtHr}, provided-interface=FeSCPR_e_Sch2CH_StrtHr
    require port FeSCPR_e_Sch2CH_StrtHr_Rx: nv-require-com-spec{init-value=Value:0, variable=FeSCPR_e_Sch2CH_StrtHr}, required-interface=FeSCPR_e_Sch2CH_StrtHr
    provide port FeSCPR_e_Sch2CH_EndMin: nv-provide-com-spec{ram-block-init-value=Value:0, rom-block-init-value=Value:0, variable=FeSCPR_e_Sch2CH_EndMin}, provided-interface=FeSCPR_e_Sch2CH_EndMin
    require port FeSCPR_e_Sch2CH_EndMin_Rx: nv-require-com-spec{init-value=Value:0, variable=FeSCPR_e_Sch2CH_EndMin}, required-interface=FeSCPR_e_Sch2CH_EndMin
    provide port FeSCPR_e_Sch2CH_EndHr: nv-provide-com-spec{ram-block-init-value=Value:0, rom-block-init-value=Value:0, variable=FeSCPR_e_Sch2CH_EndHr}, provided-interface=FeSCPR_e_Sch2CH_EndHr
    require port FeSCPR_e_Sch2CH_EndHr_Rx: nv-require-com-spec{init-value=Value:0, variable=FeSCPR_e_Sch2CH_EndHr}, required-interface=FeSCPR_e_Sch2CH_EndHr
    provide port FeSCPR_e_Sch1CP_DepMin: nv-provide-com-spec{ram-block-init-value=Value:0, rom-block-init-value=Value:0, variable=FeSCPR_e_Sch1CP_DepMin}, provided-interface=FeSCPR_e_Sch1CP_DepMin
    require port FeSCPR_e_Sch1CP_DepMin_Rx: nv-require-com-spec{init-value=Value:0, variable=FeSCPR_e_Sch1CP_DepMin}, required-interface=FeSCPR_e_Sch1CP_DepMin
    provide port FeSCPR_e_Sch1CP_DepHr: nv-provide-com-spec{ram-block-init-value=Value:0, rom-block-init-value=Value:0, variable=FeSCPR_e_Sch1CP_DepHr}, provided-interface=FeSCPR_e_Sch1CP_DepHr
    require port FeSCPR_e_Sch1CP_DepHr_Rx: nv-require-com-spec{init-value=Value:0, variable=FeSCPR_e_Sch1CP_DepHr}, required-interface=FeSCPR_e_Sch1CP_DepHr
    provide port FeSCPR_e_Sch1CH_StrtMin: nv-provide-com-spec{ram-block-init-value=Value:0, rom-block-init-value=Value:0, variable=FeSCPR_e_Sch1CH_StrtMin}, provided-interface=FeSCPR_e_Sch1CH_StrtMin
    require port FeSCPR_e_Sch1CH_StrtMin_Rx: nv-require-com-spec{init-value=Value:0, variable=FeSCPR_e_Sch1CH_StrtMin}, required-interface=FeSCPR_e_Sch1CH_StrtMin
    provide port FeSCPR_e_Sch1CH_StrtHr: nv-provide-com-spec{ram-block-init-value=Value:0, rom-block-init-value=Value:0, variable=FeSCPR_e_Sch1CH_StrtHr}, provided-interface=FeSCPR_e_Sch1CH_StrtHr
    require port FeSCPR_e_Sch1CH_StrtHr_Rx: nv-require-com-spec{init-value=Value:0, variable=FeSCPR_e_Sch1CH_StrtHr}, required-interface=FeSCPR_e_Sch1CH_StrtHr
    provide port FeSCPR_e_Sch1CH_EndMin: nv-provide-com-spec{ram-block-init-value=Value:0, rom-block-init-value=Value:0, variable=FeSCPR_e_Sch1CH_EndMin}, provided-interface=FeSCPR_e_Sch1CH_EndMin
    require port FeSCPR_e_Sch1CH_EndMin_Rx: nv-require-com-spec{init-value=Value:0, variable=FeSCPR_e_Sch1CH_EndMin}, required-interface=FeSCPR_e_Sch1CH_EndMin
    provide port FeSCPR_e_Sch1CH_EndHr: nv-provide-com-spec{ram-block-init-value=Value:0, rom-block-init-value=Value:0, variable=FeSCPR_e_Sch1CH_EndHr}, provided-interface=FeSCPR_e_Sch1CH_EndHr
    require port FeSCPR_e_Sch1CH_EndHr_Rx: nv-require-com-spec{init-value=Value:0, variable=FeSCPR_e_Sch1CH_EndHr}, required-interface=FeSCPR_e_Sch1CH_EndHr
    provide port FeSCPR_b_Sch2CP_DNR: nv-provide-com-spec{ram-block-init-value=Value:0, rom-block-init-value=Value:0, variable=FeSCPR_b_Sch2CP_DNR}, provided-interface=FeSCPR_b_Sch2CP_DNR
    require port FeSCPR_b_Sch2CP_DNR_Rx: nv-require-com-spec{init-value=Value:0, variable=FeSCPR_b_Sch2CP_DNR}, required-interface=FeSCPR_b_Sch2CP_DNR
    provide port FeSCPR_b_CancelActFOTA: nv-provide-com-spec{ram-block-init-value=Value:0, rom-block-init-value=Value:0, variable=FeSCPR_b_CancelActFOTA}, provided-interface=FeSCPR_b_CancelActFOTA
    require port FeSCPR_b_CancelActFOTA_Rx: nv-require-com-spec{init-value=Value:0, variable=FeSCPR_b_CancelActFOTA}, required-interface=FeSCPR_b_CancelActFOTA
    provide port FeSCPR_b_ChrgNowLatch: nv-provide-com-spec{ram-block-init-value=Value:0, rom-block-init-value=Value:0, variable=FeSCPR_b_ChrgNowLatch}, provided-interface=FeSCPR_b_ChrgNowLatch
    require port FeSCPR_b_ChrgNowLatch_Rx: nv-require-com-spec{init-value=Value:0, variable=FeSCPR_b_ChrgNowLatch}, required-interface=FeSCPR_b_ChrgNowLatch
    provide port FeSCPR_b_FOTA_Conflict: nv-provide-com-spec{ram-block-init-value=Value:0, rom-block-init-value=Value:0, variable=FeSCPR_b_FOTA_Conflict}, provided-interface=FeSCPR_b_FOTA_Conflict
    require port FeSCPR_b_FOTA_Conflict_Rx: nv-require-com-spec{init-value=Value:0, variable=FeSCPR_b_FOTA_Conflict}, required-interface=FeSCPR_b_FOTA_Conflict
    provide port FeSCPR_b_Sch1CH_ChrgUntFl: nv-provide-com-spec{ram-block-init-value=Value:0, rom-block-init-value=Value:0, variable=FeSCPR_b_Sch1CH_ChrgUntFl}, provided-interface=FeSCPR_b_Sch1CH_ChrgUntFl
    require port FeSCPR_b_Sch1CH_ChrgUntFl_Rx: nv-require-com-spec{init-value=Value:0, variable=FeSCPR_b_Sch1CH_ChrgUntFl}, required-interface=FeSCPR_b_Sch1CH_ChrgUntFl
    provide port FeSCPR_b_Sch1CH_DNR: nv-provide-com-spec{ram-block-init-value=Value:0, rom-block-init-value=Value:0, variable=FeSCPR_b_Sch1CH_DNR}, provided-interface=FeSCPR_b_Sch1CH_DNR
    require port FeSCPR_b_Sch1CH_DNR_Rx: nv-require-com-spec{init-value=Value:0, variable=FeSCPR_b_Sch1CH_DNR}, required-interface=FeSCPR_b_Sch1CH_DNR
    provide port FeSCPR_b_Sch1CH_Enbl: nv-provide-com-spec{ram-block-init-value=Value:0, rom-block-init-value=Value:0, variable=FeSCPR_b_Sch1CH_Enbl}, provided-interface=FeSCPR_b_Sch1CH_Enbl
    require port FeSCPR_b_Sch1CH_Enbl_Rx: nv-require-com-spec{init-value=Value:0, variable=FeSCPR_b_Sch1CH_Enbl}, required-interface=FeSCPR_b_Sch1CH_Enbl
    provide port FeSCPR_b_Sch1CP_DNR: nv-provide-com-spec{ram-block-init-value=Value:0, rom-block-init-value=Value:0, variable=FeSCPR_b_Sch1CP_DNR}, provided-interface=FeSCPR_b_Sch1CP_DNR
    require port FeSCPR_b_Sch1CP_DNR_Rx: nv-require-com-spec{init-value=Value:0, variable=FeSCPR_b_Sch1CP_DNR}, required-interface=FeSCPR_b_Sch1CP_DNR
    provide port FeSCPR_b_Sch1CP_Enbl: nv-provide-com-spec{ram-block-init-value=Value:0, rom-block-init-value=Value:0, variable=FeSCPR_b_Sch1CP_Enbl}, provided-interface=FeSCPR_b_Sch1CP_Enbl
    require port FeSCPR_b_Sch1CP_Enbl_Rx: nv-require-com-spec{init-value=Value:0, variable=FeSCPR_b_Sch1CP_Enbl}, required-interface=FeSCPR_b_Sch1CP_Enbl
    provide port FeSCPR_b_Sch2CH_ChrgUntFl: nv-provide-com-spec{ram-block-init-value=Value:0, rom-block-init-value=Value:0, variable=FeSCPR_b_Sch2CH_ChrgUntFl}, provided-interface=FeSCPR_b_Sch2CH_ChrgUntFl
    require port FeSCPR_b_Sch2CH_ChrgUntFl_Rx: nv-require-com-spec{init-value=Value:0, variable=FeSCPR_b_Sch2CH_ChrgUntFl}, required-interface=FeSCPR_b_Sch2CH_ChrgUntFl
    provide port FeSCPR_b_Sch2CH_DNR: nv-provide-com-spec{ram-block-init-value=Value:0, rom-block-init-value=Value:0, variable=FeSCPR_b_Sch2CH_DNR}, provided-interface=FeSCPR_b_Sch2CH_DNR
    require port FeSCPR_b_Sch2CH_DNR_Rx: nv-require-com-spec{init-value=Value:0, variable=FeSCPR_b_Sch2CH_DNR}, required-interface=FeSCPR_b_Sch2CH_DNR
    provide port FeSCPR_b_Sch2CH_Enbl: nv-provide-com-spec{ram-block-init-value=Value:0, rom-block-init-value=Value:0, variable=FeSCPR_b_Sch2CH_Enbl}, provided-interface=FeSCPR_b_Sch2CH_Enbl
    require port FeSCPR_b_Sch2CH_Enbl_Rx: nv-require-com-spec{init-value=Value:0, variable=FeSCPR_b_Sch2CH_Enbl}, required-interface=FeSCPR_b_Sch2CH_Enbl
    provide port FeSCPR_b_Sch2CP_Enbl: nv-provide-com-spec{ram-block-init-value=Value:0, rom-block-init-value=Value:0, variable=FeSCPR_b_Sch2CP_Enbl}, provided-interface=FeSCPR_b_Sch2CP_Enbl
    require port FeSCPR_b_Sch2CP_Enbl_Rx: nv-require-com-spec{init-value=Value:0, variable=FeSCPR_b_Sch2CP_Enbl}, required-interface=FeSCPR_b_Sch2CP_Enbl
    provide port FeSCPR_e_FOTA_Install_Type: nv-provide-com-spec{ram-block-init-value=Value:0, rom-block-init-value=Value:0, variable=FeSCPR_e_FOTA_Install_Type}, provided-interface=FeSCPR_e_FOTA_Install_Type
    require port FeSCPR_e_FOTA_Install_Type_Rx: nv-require-com-spec{init-value=Value:0, variable=FeSCPR_e_FOTA_Install_Type}, required-interface=FeSCPR_e_FOTA_Install_Type
    provide port FeSCPR_e_Sch1CP_Allow: nv-provide-com-spec{ram-block-init-value=Value:0, rom-block-init-value=Value:0, variable=FeSCPR_e_Sch1CP_Allow}, provided-interface=FeSCPR_e_Sch1CP_Allow
    require port FeSCPR_e_Sch1CP_Allow_Rx: nv-require-com-spec{init-value=Value:0, variable=FeSCPR_e_Sch1CP_Allow}, required-interface=FeSCPR_e_Sch1CP_Allow
    provide port FeSCPR_e_Sch2CP_Allow: nv-provide-com-spec{ram-block-init-value=Value:0, rom-block-init-value=Value:0, variable=FeSCPR_e_Sch2CP_Allow}, provided-interface=FeSCPR_e_Sch2CP_Allow
    require port FeSCPR_e_Sch2CP_Allow_Rx: nv-require-com-spec{init-value=Value:0, variable=FeSCPR_e_Sch2CP_Allow}, required-interface=FeSCPR_e_Sch2CP_Allow
    provide port FeSCPR_y_Sch1CH_Day: nv-provide-com-spec{ram-block-init-value=Value:0, rom-block-init-value=Value:0, variable=FeSCPR_y_Sch1CH_Day}, provided-interface=FeSCPR_y_Sch1CH_Day
    require port FeSCPR_y_Sch1CH_Day_Rx: nv-require-com-spec{init-value=Value:0, variable=FeSCPR_y_Sch1CH_Day}, required-interface=FeSCPR_y_Sch1CH_Day
    provide port FeSCPR_y_Sch1CP_Day: nv-provide-com-spec{ram-block-init-value=Value:0, rom-block-init-value=Value:0, variable=FeSCPR_y_Sch1CP_Day}, provided-interface=FeSCPR_y_Sch1CP_Day
    require port FeSCPR_y_Sch1CP_Day_Rx: nv-require-com-spec{init-value=Value:0, variable=FeSCPR_y_Sch1CP_Day}, required-interface=FeSCPR_y_Sch1CP_Day
    provide port FeSCPR_y_Sch2CH_Day: nv-provide-com-spec{ram-block-init-value=Value:0, rom-block-init-value=Value:0, variable=FeSCPR_y_Sch2CH_Day}, provided-interface=FeSCPR_y_Sch2CH_Day
    require port FeSCPR_y_Sch2CH_Day_Rx: nv-require-com-spec{init-value=Value:0, variable=FeSCPR_y_Sch2CH_Day}, required-interface=FeSCPR_y_Sch2CH_Day
    provide port FeSCPR_y_Sch2CP_Day: nv-provide-com-spec{ram-block-init-value=Value:0, rom-block-init-value=Value:0, variable=FeSCPR_y_Sch2CP_Day}, provided-interface=FeSCPR_y_Sch2CP_Day
    require port FeSCPR_y_Sch2CP_Day_Rx: nv-require-com-spec{init-value=Value:0, variable=FeSCPR_y_Sch2CP_Day}, required-interface=FeSCPR_y_Sch2CP_Day
    provide port AeASLR_v_STSLSpdLimMPH: nv-provide-com-spec{ram-block-init-value=Value:0, rom-block-init-value=Value:0, variable=AeASLR_v_STSLSpdLimMPH}, provided-interface=AeASLR_v_STSLSpdLimMPH
    require port AeASLR_v_STSLSpdLimMPH_Rx: nv-require-com-spec{init-value=Value:0, variable=AeASLR_v_STSLSpdLimMPH}, required-interface=AeASLR_v_STSLSpdLimMPH
    provide port AeDCCR_y_DCChrgTestSts: nv-provide-com-spec{ram-block-init-value=Value:0, rom-block-init-value=Value:0, variable=AeDCCR_y_DCChrgTestSts}, provided-interface=AeDCCR_y_DCChrgTestSts
    require port AeDCCR_y_DCChrgTestSts_Rx: nv-require-com-spec{init-value=Value:0, variable=AeDCCR_y_DCChrgTestSts}, required-interface=AeDCCR_y_DCChrgTestSts
    provide port AeADIR_e_WEDExtToolCmd: nv-provide-com-spec{ram-block-init-value=Value:0, rom-block-init-value=Value:0, variable=AeADIR_e_WEDExtToolCmd}, provided-interface=AeADIR_e_WEDExtToolCmd
    require port AeADIR_e_WEDExtToolCmd_Rx: nv-require-com-spec{init-value=Value:0, variable=AeADIR_e_WEDExtToolCmd}, required-interface=AeADIR_e_WEDExtToolCmd
    provide port AeTRGR_y_PwrDwnSts: nv-provide-com-spec{ram-block-init-value=Value:0, rom-block-init-value=Value:0, variable=AeTRGR_y_PwrDwnSts}, provided-interface=AeTRGR_y_PwrDwnSts
    require port AeTRGR_y_PwrDwnSts_Rx: nv-require-com-spec{init-value=Value:0, variable=AeTRGR_y_PwrDwnSts}, required-interface=AeTRGR_y_PwrDwnSts
    provide port AeRTMR_b_ElectricOnlyTest_Enabled: nv-provide-com-spec{ram-block-init-value=Value:0, rom-block-init-value=Value:0, variable=AeRTMR_b_ElectricOnlyTest_Enabled}, provided-interface=AeRTMR_b_ElectricOnlyTest_Enabled
    require port AeRTMR_b_ElectricOnlyTest_Enabled_Rx: nv-require-com-spec{init-value=Value:0, variable=AeRTMR_b_ElectricOnlyTest_Enabled}, required-interface=AeRTMR_b_ElectricOnlyTest_Enabled
    provide port AeRTMR_e_EngStrtType_LstActn: nv-provide-com-spec{ram-block-init-value=Value:0, rom-block-init-value=Value:0, variable=AeRTMR_e_EngStrtType_LstActn}, provided-interface=AeRTMR_e_EngStrtType_LstActn
    require port AeRTMR_e_EngStrtType_LstActn_Rx: nv-require-com-spec{init-value=Value:0, variable=AeRTMR_e_EngStrtType_LstActn}, required-interface=AeRTMR_e_EngStrtType_LstActn
    provide port AeRTMR_e_WED_ToothAbutResult: nv-provide-com-spec{ram-block-init-value=Value:0, rom-block-init-value=Value:0, variable=AeRTMR_e_WED_ToothAbutResult}, provided-interface=AeRTMR_e_WED_ToothAbutResult
    require port AeRTMR_e_WED_ToothAbutResult_Rx: nv-require-com-spec{init-value=Value:0, variable=AeRTMR_e_WED_ToothAbutResult}, required-interface=AeRTMR_e_WED_ToothAbutResult
    provide port AeRTMR_y_ElecOnlyTestResult_PID: nv-provide-com-spec{ram-block-init-value=Value:0, rom-block-init-value=Value:0, variable=AeRTMR_y_ElecOnlyTestResult_PID}, provided-interface=AeRTMR_y_ElecOnlyTestResult_PID
    require port AeRTMR_y_ElecOnlyTestResult_PID_Rx: nv-require-com-spec{init-value=Value:0, variable=AeRTMR_y_ElecOnlyTestResult_PID}, required-interface=AeRTMR_y_ElecOnlyTestResult_PID
    provide port AeRTMR_y_ElecOnlyTestStatus_PID: nv-provide-com-spec{ram-block-init-value=Value:0, rom-block-init-value=Value:0, variable=AeRTMR_y_ElecOnlyTestStatus_PID}, provided-interface=AeRTMR_y_ElecOnlyTestStatus_PID
    require port AeRTMR_y_ElecOnlyTestStatus_PID_Rx: nv-require-com-spec{init-value=Value:0, variable=AeRTMR_y_ElecOnlyTestStatus_PID}, required-interface=AeRTMR_y_ElecOnlyTestStatus_PID
    provide port AeIMPR_b_HVRpdShtdwnCmd: nv-provide-com-spec{ram-block-init-value=Value:0, rom-block-init-value=Value:0, variable=AeIMPR_b_HVRpdShtdwnCmd}, provided-interface=AeIMPR_b_HVRpdShtdwnCmd
    require port AeIMPR_b_HVRpdShtdwnCmd_Rx: nv-require-com-spec{init-value=Value:0, variable=AeIMPR_b_HVRpdShtdwnCmd}, required-interface=AeIMPR_b_HVRpdShtdwnCmd
    provide port AePLTR_Pct_CS_SOCSetPt: nv-provide-com-spec{ram-block-init-value=Value:0, rom-block-init-value=Value:0, variable=AePLTR_Pct_CS_SOCSetPt}, provided-interface=AePLTR_Pct_CS_SOCSetPt
    require port AePLTR_Pct_CS_SOCSetPt_Rx: nv-require-com-spec{init-value=Value:0, variable=AePLTR_Pct_CS_SOCSetPt}, required-interface=AePLTR_Pct_CS_SOCSetPt
    provide port AePLTR_Pct_IP_SOCSetPt: nv-provide-com-spec{ram-block-init-value=Value:0, rom-block-init-value=Value:0, variable=AePLTR_Pct_IP_SOCSetPt}, provided-interface=AePLTR_Pct_IP_SOCSetPt
    require port AePLTR_Pct_IP_SOCSetPt_Rx: nv-require-com-spec{init-value=Value:0, variable=AePLTR_Pct_IP_SOCSetPt}, required-interface=AePLTR_Pct_IP_SOCSetPt
    provide port AePLTR_milel_IPEETestMileageLimit: nv-provide-com-spec{ram-block-init-value=Value:0, rom-block-init-value=Value:0, variable=AePLTR_milel_IPEETestMileageLimit}, provided-interface=AePLTR_milel_IPEETestMileageLimit
    require port AePLTR_milel_IPEETestMileageLimit_Rx: nv-require-com-spec{init-value=Value:0, variable=AePLTR_milel_IPEETestMileageLimit}, required-interface=AePLTR_milel_IPEETestMileageLimit
    provide port AePLTR_milel_OdometerLimit: nv-provide-com-spec{ram-block-init-value=Value:0, rom-block-init-value=Value:0, variable=AePLTR_milel_OdometerLimit}, provided-interface=AePLTR_milel_OdometerLimit
    require port AePLTR_milel_OdometerLimit_Rx: nv-require-com-spec{init-value=Value:0, variable=AePLTR_milel_OdometerLimit}, required-interface=AePLTR_milel_OdometerLimit
    provide port AePLTR_b_InFieldMode: nv-provide-com-spec{ram-block-init-value=Value:0, rom-block-init-value=Value:0, variable=AePLTR_b_InFieldMode}, provided-interface=AePLTR_b_InFieldMode
    require port AePLTR_b_InFieldMode_Rx: nv-require-com-spec{init-value=Value:0, variable=AePLTR_b_InFieldMode}, required-interface=AePLTR_b_InFieldMode
    provide port AePLTR_b_PwrOffOk: nv-provide-com-spec{ram-block-init-value=Value:0, rom-block-init-value=Value:0, variable=AePLTR_b_PwrOffOk}, provided-interface=AePLTR_b_PwrOffOk
    require port AePLTR_b_PwrOffOk_Rx: nv-require-com-spec{init-value=Value:0, variable=AePLTR_b_PwrOffOk}, required-interface=AePLTR_b_PwrOffOk
    provide port AePLTR_b_REMDisabled: nv-provide-com-spec{ram-block-init-value=Value:0, rom-block-init-value=Value:0, variable=AePLTR_b_REMDisabled}, provided-interface=AePLTR_b_REMDisabled
    require port AePLTR_b_REMDisabled_Rx: nv-require-com-spec{init-value=Value:0, variable=AePLTR_b_REMDisabled}, required-interface=AePLTR_b_REMDisabled
    provide port AePLTR_b_RadFanHandshake_disbld: nv-provide-com-spec{ram-block-init-value=Value:0, rom-block-init-value=Value:0, variable=AePLTR_b_RadFanHandshake_disbld}, provided-interface=AePLTR_b_RadFanHandshake_disbld
    require port AePLTR_b_RadFanHandshake_disbld_Rx: nv-require-com-spec{init-value=Value:0, variable=AePLTR_b_RadFanHandshake_disbld}, required-interface=AePLTR_b_RadFanHandshake_disbld
    provide port AaIMOR_y_MMKeyStr_EE: nv-provide-com-spec{ram-block-init-value=ArrayValues:[ArrayElement0:0, ArrayElement1:0, ArrayElement2:0, ArrayElement3:0, ArrayElement4:0, ArrayElement5:0, ArrayElement6:0], rom-block-init-value=ArrayValues:[ArrayElement0:0, ArrayElement1:0, ArrayElement2:0, ArrayElement3:0, ArrayElement4:0, ArrayElement5:0, ArrayElement6:0], variable=AaIMOR_y_MMKeyStr_EE}, provided-interface=AaIMOR_y_MMKeyStr_EE
    require port AaIMOR_y_MMKeyStr_EE_Rx: nv-require-com-spec{init-value=ArrayValues:[ArrayElement0:0, ArrayElement1:0, ArrayElement2:0, ArrayElement3:0, ArrayElement4:0, ArrayElement5:0, ArrayElement6:0], variable=AaIMOR_y_MMKeyStr_EE}, required-interface=AaIMOR_y_MMKeyStr_EE
    provide port AeIMOR_b_UpdtAuthStat: nv-provide-com-spec{ram-block-init-value=Value:0, rom-block-init-value=Value:0, variable=AeIMOR_b_UpdtAuthStat}, provided-interface=AeIMOR_b_UpdtAuthStat
    require port AeIMOR_b_UpdtAuthStat_Rx: nv-require-com-spec{init-value=Value:0, variable=AeIMOR_b_UpdtAuthStat}, required-interface=AeIMOR_b_UpdtAuthStat
    provide port AeIMOR_Cnt_ImmoByPassCntr: nv-provide-com-spec{ram-block-init-value=Value:0, rom-block-init-value=Value:0, variable=AeIMOR_Cnt_ImmoByPassCntr}, provided-interface=AeIMOR_Cnt_ImmoByPassCntr
    require port AeIMOR_Cnt_ImmoByPassCntr_Rx: nv-require-com-spec{init-value=Value:0, variable=AeIMOR_Cnt_ImmoByPassCntr}, required-interface=AeIMOR_Cnt_ImmoByPassCntr
    behavior IB_NvBlkSWC_4: data-type-mapping=NVM_DataMappingSet, handle-termination-and-restart=NO-SUPPORT
      21 x data received event:
        DataReceivedEvent_AeASLR_v_STSLSpdLimMPH: start-on-event=RE_AeASLR_v_STSLSpdLimMPH, data=AeASLR_v_STSLSpdLimMPH_Rx.AeASLR_v_STSLSpdLimMPH
        DataReceivedEvent_AeDCCR_y_DCChrgTestSts: start-on-event=RE_AeDCCR_y_DCChrgTestSts, data=AeDCCR_y_DCChrgTestSts_Rx.AeDCCR_y_DCChrgTestSts
        DataReceivedEvent_AeADIR_e_WEDExtToolCmd: start-on-event=RE_AeADIR_e_WEDExtToolCmd, data=AeADIR_e_WEDExtToolCmd_Rx.AeADIR_e_WEDExtToolCmd
        DataReceivedEvent_AeTRGR_y_PwrDwnSts: start-on-event=RE_AeTRGR_y_PwrDwnSts, data=AeTRGR_y_PwrDwnSts_Rx.AeTRGR_y_PwrDwnSts
        DataReceivedEvent_AeRTMR_b_ElectricOnlyTest_Enabled: start-on-event=RE_AeRTMR_b_ElectricOnlyTest_Enabled, data=AeRTMR_b_ElectricOnlyTest_Enabled_Rx.AeRTMR_b_ElectricOnlyTest_Enabled
        DataReceivedEvent_AeRTMR_e_EngStrtType_LstActn: start-on-event=RE_AeRTMR_e_EngStrtType_LstActn, data=AeRTMR_e_EngStrtType_LstActn_Rx.AeRTMR_e_EngStrtType_LstActn
        DataReceivedEvent_AeRTMR_e_WED_ToothAbutResult: start-on-event=RE_AeRTMR_e_WED_ToothAbutResult, data=AeRTMR_e_WED_ToothAbutResult_Rx.AeRTMR_e_WED_ToothAbutResult
        DataReceivedEvent_AeRTMR_y_ElecOnlyTestResult_PID: start-on-event=RE_AeRTMR_y_ElecOnlyTestResult_PID, data=AeRTMR_y_ElecOnlyTestResult_PID_Rx.AeRTMR_y_ElecOnlyTestResult_PID
        DataReceivedEvent_AeRTMR_y_ElecOnlyTestStatus_PID: start-on-event=RE_AeRTMR_y_ElecOnlyTestStatus_PID, data=AeRTMR_y_ElecOnlyTestStatus_PID_Rx.AeRTMR_y_ElecOnlyTestStatus_PID
        DataReceivedEvent_AeIMPR_b_HVRpdShtdwnCmd: start-on-event=RE_AeIMPR_b_HVRpdShtdwnCmd, data=AeIMPR_b_HVRpdShtdwnCmd_Rx.AeIMPR_b_HVRpdShtdwnCmd
        DataReceivedEvent_AePLTR_Pct_CS_SOCSetPt: start-on-event=RE_AePLTR_Pct_CS_SOCSetPt, data=AePLTR_Pct_CS_SOCSetPt_Rx.AePLTR_Pct_CS_SOCSetPt
        DataReceivedEvent_AePLTR_Pct_IP_SOCSetPt: start-on-event=RE_AePLTR_Pct_IP_SOCSetPt, data=AePLTR_Pct_IP_SOCSetPt_Rx.AePLTR_Pct_IP_SOCSetPt
        DataReceivedEvent_AePLTR_milel_IPEETestMileageLimit: start-on-event=RE_AePLTR_milel_IPEETestMileageLimit, data=AePLTR_milel_IPEETestMileageLimit_Rx.AePLTR_milel_IPEETestMileageLimit
        DataReceivedEvent_AePLTR_milel_OdometerLimit: start-on-event=RE_AePLTR_milel_OdometerLimit, data=AePLTR_milel_OdometerLimit_Rx.AePLTR_milel_OdometerLimit
        DataReceivedEvent_AePLTR_b_InFieldMode: start-on-event=RE_AePLTR_b_InFieldMode, data=AePLTR_b_InFieldMode_Rx.AePLTR_b_InFieldMode
        DataReceivedEvent_AePLTR_b_PwrOffOk: start-on-event=RE_AePLTR_b_PwrOffOk, data=AePLTR_b_PwrOffOk_Rx.AePLTR_b_PwrOffOk
        DataReceivedEvent_AePLTR_b_REMDisabled: start-on-event=RE_AePLTR_b_REMDisabled, data=AePLTR_b_REMDisabled_Rx.AePLTR_b_REMDisabled
        DataReceivedEvent_AePLTR_b_RadFanHandshake_disbld: start-on-event=RE_AePLTR_b_RadFanHandshake_disbld, data=AePLTR_b_RadFanHandshake_disbld_Rx.AePLTR_b_RadFanHandshake_disbld
        DataReceivedEvent_EE_IMMOBILIZERMMKEY_StrIMM: start-on-event=RE_EE_IMMOBILIZERMMKEY_StrIMM, data=AaIMOR_y_MMKeyStr_EE_Rx.AaIMOR_y_MMKeyStr_EE
        DataReceivedEvent_EE_IMMOBILIZERAUTHSTAT_StrIMM_Descr: start-on-event=RE_EE_IMMOBILIZERAUTHSTAT_StrIMM, data=AeIMOR_b_UpdtAuthStat_Rx.AeIMOR_b_UpdtAuthStat
        DataReceivedEvent_EE_IMMOBYPASSCNTR_StrIMM: start-on-event=RE_EE_IMMOBYPASSCNTR_StrIMM, data=AeIMOR_Cnt_ImmoByPassCntr_Rx.AeIMOR_Cnt_ImmoByPassCntr
      21 x runnable:
        RE_AeASLR_v_STSLSpdLimMPH
        RE_AeDCCR_y_DCChrgTestSts
        RE_AeADIR_e_WEDExtToolCmd
        RE_AeTRGR_y_PwrDwnSts
        RE_AeRTMR_b_ElectricOnlyTest_Enabled
        RE_AeRTMR_e_EngStrtType_LstActn
        RE_AeRTMR_e_WED_ToothAbutResult
        RE_AeRTMR_y_ElecOnlyTestResult_PID
        RE_AeRTMR_y_ElecOnlyTestStatus_PID
        RE_AeIMPR_b_HVRpdShtdwnCmd
        RE_AePLTR_Pct_CS_SOCSetPt
        RE_AePLTR_Pct_IP_SOCSetPt
        RE_AePLTR_milel_IPEETestMileageLimit
        RE_AePLTR_milel_OdometerLimit
        RE_AePLTR_b_InFieldMode
        RE_AePLTR_b_PwrOffOk
        RE_AePLTR_b_REMDisabled
        RE_AePLTR_b_RadFanHandshake_disbld
        RE_EE_IMMOBILIZERMMKEY_StrIMM: symbol=EE_IMMOBILIZERMMKEY_StrIMM
        RE_EE_IMMOBILIZERAUTHSTAT_StrIMM: symbol=EE_IMMOBILIZERAUTHSTAT_StrIMM
        RE_EE_IMMOBYPASSCNTR_StrIMM: symbol=EE_IMMOBYPASSCNTR_StrIMM
